[part 1 of 6: package /DBC_SysDesc_P_CANFD/Pkg_Cluster]
AUTOSAR XML (schema 4-2-2)
package /DBC_SysDesc_P_CANFD/Pkg_Cluster
  can cluster P_CANFD: baudrate=500000, protocol-name=CAN, can-fd-baudrate=2000000
    can physical channel P_CANFD_Channel: comm-connectors=Conn_P_CANFD_MVCU
      frame EMS_0xBE: id 0xBE, to MVCU, frame-length=32, can-addressing-mode=STANDARD, can-fd-frame-support=true, can-frame-rx-behavior=CAN-FD
        carries pdu EMS_0xBE: packing-byte-order=little-endian, start-position=0, update-indication-bit-position=-1
        pdu EMS_0xBE: length=32, transmission-mode-false-timing=cyclic-timing={time-offset=0.0, time-period=0.01}, transmission-mode-true-timing=cyclic-timing={time-offset=0.0, time-period=0.01}
          transmission-mode-conditions:
            {data-filter={data-filter-type=ALWAYS, max=255, min=0, offset=0}, i-signal-in-i-pdu=EMS_CRC_BE}
            {data-filter={data-filter-type=ALWAYS, max=15, min=0, offset=0}, i-signal-in-i-pdu=EMS_RollingCounter_BE}
            {data-filter={data-filter-type=ALWAYS, max=7, min=0, offset=0}, i-signal-in-i-pdu=EMS_EngineSts}
            {data-filter={data-filter-type=ALWAYS, max=3, min=0, offset=0}, i-signal-in-i-pdu=ECM_FaultLevel}
            {data-filter={data-filter-type=ALWAYS, max=1, min=0, offset=0}, i-signal-in-i-pdu=ECM_ActualEngineTorqueValid}
            {data-filter={data-filter-type=NEW-IS-WITHIN, max=1022, min=0}, i-signal-in-i-pdu=ECM_EngineTorqueLoss}
            {data-filter={data-filter-type=NEW-IS-WITHIN, max=4094, min=0}, i-signal-in-i-pdu=ECM_ActualEngineTorque}
            {data-filter={data-filter-type=NEW-IS-WITHIN, max=4094, min=0}, i-signal-in-i-pdu=ECM_EngineTorqueMax}
            {data-filter={data-filter-type=NEW-IS-WITHIN, max=4094, min=0}, i-signal-in-i-pdu=ECM_EngineTorqueMin}
            {data-filter={data-filter-type=NEW-IS-WITHIN, max=8191, min=0, offset=0}, i-signal-in-i-pdu=ECM_EngineSpeed}
            {data-filter={data-filter-type=ALWAYS, max=1, min=0, offset=0}, i-signal-in-i-pdu=ECM_EngineSpeedValid}
            {data-filter={data-filter-type=ALWAYS, max=1, min=0, offset=0}, i-signal-in-i-pdu=ECM_EngineStopAllow}
            {data-filter={data-filter-type=ALWAYS, max=1, min=0, offset=0}, i-signal-in-i-pdu=ECM_EngineOilPressureLow}
            {data-filter={data-filter-type=ALWAYS, max=1, min=0, offset=0}, i-signal-in-i-pdu=ECM_EngineFuleCutoffSts}
            {data-filter={data-filter-type=ALWAYS, max=1, min=0, offset=0}, i-signal-in-i-pdu=ECM_EngineStartedCompleted}
            {data-filter={data-filter-type=ALWAYS, max=1, min=0, offset=0}, i-signal-in-i-pdu=ECM_CatalystWarmUpSts}
            {data-filter={data-filter-type=ALWAYS, max=1, min=0, offset=0}, i-signal-in-i-pdu=ECM_CatalystWarmUpReq}
            {data-filter={data-filter-type=NEW-IS-WITHIN, max=4094, min=0, offset=0}, i-signal-in-i-pdu=ECM_IdleTargetSpeed}
            {data-filter={data-filter-type=ALWAYS, max=1, min=0, offset=0}, i-signal-in-i-pdu=ECM_IdleActive}
            {data-filter={data-filter-type=ALWAYS, max=7, min=0, offset=0}, i-signal-in-i-pdu=ECM_EngineStartReq}
            {data-filter={data-filter-type=NEW-IS-WITHIN, max=1023, min=0, offset=0}, i-signal-in-i-pdu=ECM_EngineStopInhibit}
            {data-filter={data-filter-type=ALWAYS, max=3, min=0, offset=0}, i-signal-in-i-pdu=ECM_GPFRegenlamp}
            {data-filter={data-filter-type=ALWAYS, max=255, min=0}, i-signal-in-i-pdu=ECM_EngineCoolantTemp}
            {data-filter={data-filter-type=ALWAYS, max=1, min=0, offset=0}, i-signal-in-i-pdu=ECM_EngineCoolantTempValid}
            {data-filter={data-filter-type=ALWAYS, max=3, min=0, offset=0}, i-signal-in-i-pdu=ECM_FVVSts}
            {data-filter={data-filter-type=ALWAYS, max=1, min=0, offset=0}, i-signal-in-i-pdu=ECM_learningReq}
            {data-filter={data-filter-type=ALWAYS, max=1, min=0, offset=0}, i-signal-in-i-pdu=ECM_EngineIdleStateRequest}
            {data-filter={data-filter-type=ALWAYS, max=1, min=0, offset=0}, i-signal-in-i-pdu=ECM_EngineDFCOConditionRequest}
            {data-filter={data-filter-type=ALWAYS, max=1, min=0, offset=0}, i-signal-in-i-pdu=ECM_GPFRegenReq}
            {data-filter={data-filter-type=ALWAYS, max=1, min=0, offset=0}, i-signal-in-i-pdu=ECM_SVSLampRequest}
            {data-filter={data-filter-type=NEW-IS-WITHIN, max=600, min=0}, i-signal-in-i-pdu=ECM_TankPressure}
            {data-filter={data-filter-type=ALWAYS, max=1, min=0, offset=0}, i-signal-in-i-pdu=ECM_TankPressureValid}
            {data-filter={data-filter-type=ALWAYS, max=3, min=0, offset=0}, i-signal-in-i-pdu=ECM_MilLampRequest}
            {data-filter={data-filter-type=ALWAYS, max=3, min=0, offset=0}, i-signal-in-i-pdu=ECM_ToothlearningSucValid}
            {data-filter={data-filter-type=ALWAYS, max=1, min=0, offset=0}, i-signal-in-i-pdu=ECM_FuelCloseLoopSts}
            {data-filter={data-filter-type=ALWAYS, max=100, min=0, offset=0}, i-signal-in-i-pdu=ECM_RestrictorOpenValue}
            {data-filter={data-filter-type=ALWAYS, max=1, min=0, offset=0}, i-signal-in-i-pdu=ECM_FuelLevelSensorValid}
            {data-filter={data-filter-type=NEW-IS-WITHIN, max=1000, min=0, offset=0}, i-signal-in-i-pdu=ECM_FuelLevel}
            {data-filter={data-filter-type=ALWAYS, max=1, min=0, offset=0}, i-signal-in-i-pdu=ECM_SelfCheckSt}
            {data-filter={data-filter-type=ALWAYS, max=1, min=0, offset=0}, i-signal-in-i-pdu=ECM_PCVPipeDiagReq}
            {data-filter={data-filter-type=NEW-IS-WITHIN, max=1000, min=0, offset=0}, i-signal-in-i-pdu=ECM_CalculatedLoad}
            {data-filter={data-filter-type=ALWAYS, max=254, min=0, offset=0}, i-signal-in-i-pdu=ECM_ClearingSparkcarbonedRequest}
            {data-filter={data-filter-type=ALWAYS, max=3, min=0, offset=0}, i-signal-in-i-pdu=ECM_AirPressure}
            {data-filter={data-filter-type=ALWAYS, max=100, min=0, offset=0}, i-signal-in-i-pdu=ECM_FanSts}
          signal EMS_CRC_BE: start 0, 8 bit, little-endian, init-value=0, base-type=uint8, implementation-data-type=DT_EMS_CRC_BE, update-indication-bit-position=-1, to MVCU
          signal EMS_RollingCounter_BE: start 8, 4 bit, little-endian, init-value=0, base-type=uint8, implementation-data-type=DT_EMS_RollingCounter_BE, update-indication-bit-position=-1, to MVCU
          signal EMS_EngineSts: start 16, 3 bit, little-endian, init-value=0, base-type=uint8, implementation-data-type=DT_EMS_EngineSts, update-indication-bit-position=-1, to MVCU
          signal ECM_FaultLevel: start 19, 2 bit, little-endian, init-value=0, base-type=uint8, implementation-data-type=DT_ECM_FaultLevel, update-indication-bit-position=-1, to MVCU
          signal ECM_ActualEngineTorqueValid: start 21, 1 bit, little-endian, init-value=0, base-type=uint8, implementation-data-type=DT_ECM_ActualEngineTorqueValid, update-indication-bit-position=-1, to MVCU
          signal ECM_EngineTorqueLoss: start 22, 10 bit, little-endian, init-value=0, base-type=uint16, implementation-data-type=DT_ECM_EngineTorqueLoss, update-indication-bit-position=-1, to MVCU
          signal ECM_ActualEngineTorque: start 32, 12 bit, little-endian, init-value=0, base-type=uint16, implementation-data-type=DT_ECM_ActualEngineTorque, update-indication-bit-position=-1, to MVCU
          signal ECM_EngineTorqueMax: start 44, 12 bit, little-endian, init-value=0, base-type=uint16, implementation-data-type=DT_ECM_EngineTorqueMax, update-indication-bit-position=-1, to MVCU
          signal ECM_EngineTorqueMin: start 56, 12 bit, little-endian, init-value=0, base-type=uint16, implementation-data-type=DT_ECM_EngineTorqueMin, update-indication-bit-position=-1, to MVCU
          signal ECM_EngineSpeed: start 68, 13 bit, little-endian, init-value=0, base-type=uint16, implementation-data-type=DT_ECM_EngineSpeed, update-indication-bit-position=-1, to MVCU
          signal ECM_EngineSpeedValid: start 81, 1 bit, little-endian, init-value=0, base-type=uint8, implementation-data-type=DT_ECM_EngineSpeedValid, update-indication-bit-position=-1, to MVCU
          signal ECM_EngineStopAllow: start 82, 1 bit, little-endian, init-value=0, base-type=uint8, implementation-data-type=DT_ECM_EngineStopAllow, update-indication-bit-position=-1, to MVCU
          signal ECM_EngineOilPressureLow: start 83, 1 bit, little-endian, init-value=0, base-type=uint8, implementation-data-type=DT_ECM_EngineOilPressureLow, update-indication-bit-position=-1, to MVCU
          signal ECM_EngineFuleCutoffSts: start 84, 1 bit, little-endian, init-value=0, base-type=uint8, implementation-data-type=DT_ECM_EngineFuleCutoffSts, update-indication-bit-position=-1, to MVCU
          signal ECM_EngineStartedCompleted: start 85, 1 bit, little-endian, init-value=0, base-type=uint8, implementation-data-type=DT_ECM_EngineStartedCompleted, update-indication-bit-position=-1, to MVCU
          signal ECM_CatalystWarmUpSts: start 86, 1 bit, little-endian, init-value=0, base-type=uint8, implementation-data-type=DT_ECM_CatalystWarmUpSts, update-indication-bit-position=-1, to MVCU
          signal ECM_CatalystWarmUpReq: start 87, 1 bit, little-endian, init-value=0, base-type=uint8, implementation-data-type=DT_ECM_CatalystWarmUpReq, update-indication-bit-position=-1, to MVCU
          signal ECM_IdleTargetSpeed: start 88, 12 bit, little-endian, init-value=0, base-type=uint16, implementation-data-type=DT_ECM_IdleTargetSpeed, update-indication-bit-position=-1, to MVCU
          signal ECM_IdleActive: start 100, 1 bit, little-endian, init-value=0, base-type=uint8, implementation-data-type=DT_ECM_IdleActive, update-indication-bit-position=-1, to MVCU
          signal ECM_EngineStartReq: start 101, 3 bit, little-endian, init-value=0, base-type=uint8, implementation-data-type=DT_ECM_EngineStartReq, update-indication-bit-position=-1, to MVCU
          signal ECM_EngineStopInhibit: start 104, 10 bit, little-endian, init-value=0, base-type=uint16, implementation-data-type=DT_ECM_EngineStopInhibit, update-indication-bit-position=-1, to MVCU
          signal ECM_GPFRegenlamp: start 114, 2 bit, little-endian, init-value=0, base-type=uint8, implementation-data-type=DT_ECM_GPFRegenlamp, update-indication-bit-position=-1, to MVCU
          signal ECM_EngineCoolantTemp: start 136, 8 bit, little-endian, init-value=0, base-type=uint8, implementation-data-type=DT_ECM_EngineCoolantTemp, update-indication-bit-position=-1, to MVCU
          signal ECM_EngineCoolantTempValid: start 144, 1 bit, little-endian, init-value=0, base-type=uint8, implementation-data-type=DT_ECM_EngineCoolantTempValid, update-indication-bit-position=-1, to MVCU
          signal ECM_FVVSts: start 145, 2 bit, little-endian, init-value=0, base-type=uint8, implementation-data-type=DT_ECM_FVVSts, update-indication-bit-position=-1, to MVCU
          signal ECM_learningReq: start 147, 1 bit, little-endian, init-value=0, base-type=uint8, implementation-data-type=DT_ECM_learningReq, update-indication-bit-position=-1, to MVCU
          signal ECM_EngineIdleStateRequest: start 148, 1 bit, little-endian, init-value=0, base-type=uint8, implementation-data-type=DT_ECM_EngineIdleStateRequest, update-indication-bit-position=-1, to MVCU
          signal ECM_EngineDFCOConditionRequest: start 149, 1 bit, little-endian, init-value=0, base-type=uint8, implementation-data-type=DT_ECM_EngineDFCOConditionRequest, update-indication-bit-position=-1, to MVCU
          signal ECM_GPFRegenReq: start 150, 1 bit, little-endian, init-value=0, base-type=uint8, implementation-data-type=DT_ECM_GPFRegenReq, update-indication-bit-position=-1, to MVCU
          signal ECM_SVSLampRequest: start 151, 1 bit, little-endian, init-value=0, base-type=uint8, implementation-data-type=DT_ECM_SVSLampRequest, update-indication-bit-position=-1, to MVCU
          signal ECM_TankPressure: start 152, 10 bit, little-endian, init-value=0, base-type=uint16, implementation-data-type=DT_ECM_TankPressure, update-indication-bit-position=-1, to MVCU
          signal ECM_TankPressureValid: start 162, 1 bit, little-endian, init-value=0, base-type=uint8, implementation-data-type=DT_ECM_TankPressureValid, update-indication-bit-position=-1, to MVCU
          signal ECM_MilLampRequest: start 163, 2 bit, little-endian, init-value=0, base-type=uint8, implementation-data-type=DT_ECM_MilLampRequest, update-indication-bit-position=-1, to MVCU
          signal ECM_ToothlearningSucValid: start 165, 2 bit, little-endian, init-value=0, base-type=uint8, implementation-data-type=DT_ECM_ToothlearningSucValid, update-indication-bit-position=-1, to MVCU
          signal ECM_FuelCloseLoopSts: start 167, 1 bit, little-endian, init-value=0, base-type=uint8, implementation-data-type=DT_ECM_FuelCloseLoopSts, update-indication-bit-position=-1, to MVCU
          signal ECM_RestrictorOpenValue: start 168, 7 bit, little-endian, init-value=0, base-type=uint8, implementation-data-type=DT_ECM_RestrictorOpenValue, update-indication-bit-position=-1, to MVCU
          signal ECM_FuelLevelSensorValid: start 175, 1 bit, little-endian, init-value=0, base-type=uint8, implementation-data-type=DT_ECM_FuelLevelSensorValid, update-indication-bit-position=-1, to MVCU
          signal ECM_FuelLevel: start 176, 10 bit, little-endian, init-value=0, base-type=uint16, implementation-data-type=DT_ECM_FuelLevel, update-indication-bit-position=-1, to MVCU
          signal ECM_SelfCheckSt: start 186, 1 bit, little-endian, init-value=0, base-type=uint8, implementation-data-type=DT_ECM_SelfCheckSt, update-indication-bit-position=-1, to MVCU
          signal ECM_PCVPipeDiagReq: start 187, 1 bit, little-endian, init-value=0, base-type=uint8, implementation-data-type=DT_ECM_PCVPipeDiagReq, update-indication-bit-position=-1, to MVCU
          signal ECM_CalculatedLoad: start 190, 10 bit, little-endian, init-value=0, base-type=uint16, implementation-data-type=DT_ECM_CalculatedLoad, update-indication-bit-position=-1, to MVCU
          signal ECM_ClearingSparkcarbonedRequest: start 203, 2 bit, little-endian, init-value=0, base-type=uint8, implementation-data-type=DT_ECM_ClearingSparkcarbonedRequest, update-indication-bit-position=-1, to MVCU
          signal ECM_AirPressure: start 208, 8 bit, little-endian, init-value=0, base-type=uint8, implementation-data-type=DT_ECM_AirPressure, update-indication-bit-position=-1, to MVCU
          signal ECM_FanSts: start 216, 8 bit, little-endian, init-value=0, base-type=uint8, implementation-data-type=DT_ECM_FanSts, update-indication-bit-position=-1, to MVCU
      frame BMS_0x5B5: id 0x5B5, to MVCU, frame-length=64, can-addressing-mode=STANDARD, can-fd-frame-support=true, can-frame-rx-behavior=CAN-FD
        carries pdu BMS_0x5B5: packing-byte-order=little-endian, start-position=0, update-indication-bit-position=-1
        pdu BMS_0x5B5: length=64, transmission-mode-false-timing=cyclic-timing={time-offset=0.0, time-period=0.2}, transmission-mode-true-timing=cyclic-timing={time-offset=0.0, time-period=0.2}
          transmission-mode-conditions:
            {data-filter={data-filter-type=ALWAYS, max=250, min=0, offset=0}, i-signal-in-i-pdu=BMS_WkupVolt_DC12V}
            {data-filter={data-filter-type=ALWAYS, max=250, min=0, offset=0}, i-signal-in-i-pdu=BMS_WkupVolt_AC12V}
            {data-filter={data-filter-type=NEW-IS-WITHIN, max=2000, min=0, offset=0}, i-signal-in-i-pdu=BMS_HVPackPosRelayExternalVolt}
            {data-filter={data-filter-type=NEW-IS-WITHIN, max=1000, min=0, offset=0}, i-signal-in-i-pdu=BMS_SOC_target}
            {data-filter={data-filter-type=NEW-IS-WITHIN, max=1000, min=0, offset=0}, i-signal-in-i-pdu=BMS_CorrectSOEPer}
            {data-filter={data-filter-type=ALWAYS, max=1, min=0, offset=0}, i-signal-in-i-pdu=BMS_SOCModifyFlag}
            {data-filter={data-filter-type=NEW-IS-WITHIN, max=16000000, min=0, offset=0}, i-signal-in-i-pdu=BMS_BMU_SoftwareVersion}
          signal BMS_WkupVolt_DC12V: start 64, 8 bit, little-endian, init-value=0, base-type=uint8, implementation-data-type=DT_BMS_WkupVolt_DC12V, update-indication-bit-position=-1, to MVCU
          signal BMS_WkupVolt_AC12V: start 72, 8 bit, little-endian, init-value=0, base-type=uint8, implementation-data-type=DT_BMS_WkupVolt_AC12V, update-indication-bit-position=-1, to MVCU
          signal BMS_HVPackPosRelayExternalVolt: start 152, 12 bit, little-endian, init-value=0, base-type=uint16, implementation-data-type=DT_BMS_HVPackPosRelayExternalVolt, update-indication-bit-position=-1, to MVCU
          signal BMS_SOC_target: start 192, 10 bit, little-endian, init-value=0, base-type=uint16, implementation-data-type=DT_BMS_SOC_target, update-indication-bit-position=-1, to MVCU
          signal BMS_CorrectSOEPer: start 202, 10 bit, little-endian, init-value=0, base-type=uint16, implementation-data-type=DT_BMS_CorrectSOEPer, update-indication-bit-position=-1, to MVCU
          signal BMS_SOCModifyFlag: start 212, 1 bit, little-endian, init-value=0, base-type=uint8, implementation-data-type=DT_BMS_SOCModifyFlag, update-indication-bit-position=-1, to MVCU
          signal BMS_BMU_SoftwareVersion: start 232, 24 bit, little-endian, init-value=0, base-type=uint32, implementation-data-type=DT_BMS_BMU_SoftwareVersion, update-indication-bit-position=-1, to MVCU
      frame OBC_0x316: id 0x316, to MVCU, frame-length=32, can-addressing-mode=STANDARD, can-fd-frame-support=true, can-frame-rx-behavior=CAN-FD
        carries pdu OBC_0x316: packing-byte-order=little-endian, start-position=0, update-indication-bit-position=-1
        pdu OBC_0x316: length=32, transmission-mode-false-timing=cyclic-timing={time-offset=0.0, time-period=0.2}, transmission-mode-true-timing=cyclic-timing={time-offset=0.0, time-period=0.2}
          transmission-mode-conditions:
            {data-filter={data-filter-type=ALWAYS, max=255, min=0, offset=0}, i-signal-in-i-pdu=OBC_CRC_316}
            {data-filter={data-filter-type=ALWAYS, max=15, min=0, offset=0}, i-signal-in-i-pdu=OBC_RollingCounter_316}
            {data-filter={data-filter-type=ALWAYS, max=7, min=0, offset=0}, i-signal-in-i-pdu=OBC_WorkSts}
            {data-filter={data-filter-type=ALWAYS, max=1, min=0, offset=0}, i-signal-in-i-pdu=OBC_StartSts}
            {data-filter={data-filter-type=ALWAYS, max=1, min=0, offset=0}, i-signal-in-i-pdu=OBC_DCSts}
            {data-filter={data-filter-type=ALWAYS, max=1, min=0, offset=0}, i-signal-in-i-pdu=OBC_ACChargeOutputSts}
            {data-filter={data-filter-type=NEW-IS-WITHIN, max=10000, min=0, offset=0}, i-signal-in-i-pdu=OBC_DCVolt}
            {data-filter={data-filter-type=ALWAYS, max=1, min=0, offset=0}, i-signal-in-i-pdu=OBC_HardwareSts}
            {data-filter={data-filter-type=NEW-IS-WITHIN, max=2000, min=0}, i-signal-in-i-pdu=OBC_DCCurr}
            {data-filter={data-filter-type=NEW-IS-WITHIN, max=8000, min=0, offset=0}, i-signal-in-i-pdu=OBC_ACVolt}
            {data-filter={data-filter-type=NEW-IS-WITHIN, max=2000, min=0}, i-signal-in-i-pdu=OBC_ACCurr}
            {data-filter={data-filter-type=ALWAYS, max=3, min=0, offset=0}, i-signal-in-i-pdu=OBC_CCConnectSts}
            {data-filter={data-filter-type=ALWAYS, max=1, min=0, offset=0}, i-signal-in-i-pdu=OBC_CPDutyCycleFault}
            {data-filter={data-filter-type=ALWAYS, max=100, min=0, offset=0}, i-signal-in-i-pdu=OBC_CPDutyCycleValue}
            {data-filter={data-filter-type=NEW-IS-WITHIN, max=1000, min=0}, i-signal-in-i-pdu=OBC_ACMaxPower}
            {data-filter={data-filter-type=ALWAYS, max=3, min=0, offset=0}, i-signal-in-i-pdu=OBC_ACPowerState}
          signal OBC_CRC_316: start 0, 8 bit, little-endian, init-value=0, base-type=uint8, implementation-data-type=DT_OBC_CRC_316, update-indication-bit-position=-1, to MVCU
          signal OBC_RollingCounter_316: start 8, 4 bit, little-endian, init-value=0, base-type=uint8, implementation-data-type=DT_OBC_RollingCounter_316, update-indication-bit-position=-1, to MVCU
          signal OBC_WorkSts: start 16, 3 bit, little-endian, init-value=0, base-type=uint8, implementation-data-type=DT_OBC_WorkSts, update-indication-bit-position=-1, to MVCU
          signal OBC_StartSts: start 19, 1 bit, little-endian, init-value=0, base-type=uint8, implementation-data-type=DT_OBC_StartSts, update-indication-bit-position=-1, to MVCU
          signal OBC_DCSts: start 20, 1 bit, little-endian, init-value=0, base-type=uint8, implementation-data-type=DT_OBC_DCSts, update-indication-bit-position=-1, to MVCU
          signal OBC_ACChargeOutputSts: start 23, 1 bit, little-endian, init-value=0, base-type=uint8, implementation-data-type=DT_OBC_ACChargeOutputSts, update-indication-bit-position=-1, to MVCU
          signal OBC_DCVolt: start 24, 14 bit, little-endian, init-value=0, base-type=uint16, implementation-data-type=DT_OBC_DCVolt, update-indication-bit-position=-1, to MVCU
          signal OBC_HardwareSts: start 39, 1 bit, little-endian, init-value=0, base-type=uint8, implementation-data-type=DT_OBC_HardwareSts, update-indication-bit-position=-1, to MVCU
          signal OBC_DCCurr: start 40, 11 bit, little-endian, init-value=0, base-type=uint16, implementation-data-type=DT_OBC_DCCurr, update-indication-bit-position=-1, to MVCU
          signal OBC_ACVolt: start 51, 13 bit, little-endian, init-value=0, base-type=uint16, implementation-data-type=DT_OBC_ACVolt, update-indication-bit-position=-1, to MVCU
          signal OBC_ACCurr: start 64, 11 bit, little-endian, init-value=0, base-type=uint16, implementation-data-type=DT_OBC_ACCurr, update-indication-bit-position=-1, to MVCU
          signal OBC_CCConnectSts: start 77, 2 bit, little-endian, init-value=0, base-type=uint8, implementation-data-type=DT_OBC_CCConnectSts, update-indication-bit-position=-1, to MVCU
          signal OBC_CPDutyCycleFault: start 79, 1 bit, little-endian, init-value=0, base-type=uint8, implementation-data-type=DT_OBC_CPDutyCycleFault, update-indication-bit-position=-1, to MVCU
          signal OBC_CPDutyCycleValue: start 80, 8 bit, little-endian, init-value=0, base-type=uint8, implementation-data-type=DT_OBC_CPDutyCycleValue, update-indication-bit-position=-1, to MVCU
          signal OBC_ACMaxPower: start 88, 10 bit, little-endian, init-value=0, base-type=uint16, implementation-data-type=DT_OBC_ACMaxPower, update-indication-bit-position=-1, to MVCU
          signal OBC_ACPowerState: start 158, 2 bit, little-endian, init-value=0, base-type=uint8, implementation-data-type=DT_OBC_ACPowerState, update-indication-bit-position=-1, to MVCU
      frame TMS_0x5FF: id 0x5FF, to MVCU, frame-length=16, can-addressing-mode=STANDARD, can-fd-frame-support=true, can-frame-rx-behavior=CAN-FD
        carries pdu TMS_0x5FF: packing-byte-order=little-endian, start-position=0, update-indication-bit-position=-1
        pdu TMS_0x5FF: length=16, transmission-mode-false-timing=cyclic-timing={time-offset=0.0, time-period=0.2}, transmission-mode-true-timing=cyclic-timing={time-offset=0.0, time-period=0.2}
          transmission-mode-conditions:
            {data-filter={data-filter-type=ALWAYS, max=128, min=0, offset=0}, i-signal-in-i-pdu=TMS_MCUMHeatPwrReq}
            {data-filter={data-filter-type=ALWAYS, max=1, min=0, offset=0}, i-signal-in-i-pdu=TMS_MCUMHeatModEnad}
            {data-filter={data-filter-type=ALWAYS, max=1, min=0, offset=0}, i-signal-in-i-pdu=TMS_VCU_MotSelfHeatEnReq}
            {data-filter={data-filter-type=ALWAYS, max=15, min=0, offset=0}, i-signal-in-i-pdu=TMS_VCU_MotSelfHeatLvlReq}
          signal TMS_MCUMHeatPwrReq: start 64, 8 bit, little-endian, init-value=0, base-type=uint8, implementation-data-type=DT_TMS_MCUMHeatPwrReq, update-indication-bit-position=-1, to MVCU
          signal TMS_MCUMHeatModEnad: start 72, 1 bit, little-endian, init-value=0, base-type=uint8, implementation-data-type=DT_TMS_MCUMHeatModEnad, update-indication-bit-position=-1, to MVCU
          signal TMS_VCU_MotSelfHeatEnReq: start 60, 1 bit, little-endian, init-value=0, base-type=uint8, implementation-data-type=DT_TMS_VCU_MotSelfHeatEnReq, update-indication-bit-position=-1, to MVCU
          signal TMS_VCU_MotSelfHeatLvlReq: start 73, 4 bit, little-endian, init-value=0, base-type=uint8, implementation-data-type=DT_TMS_VCU_MotSelfHeatLvlReq, update-indication-bit-position=-1, to MVCU
      frame TMS_0x5FE: id 0x5FE, to MVCU, frame-length=8, can-addressing-mode=STANDARD, can-fd-frame-support=true, can-frame-rx-behavior=CAN-FD
        carries pdu TMS_0x5FE: packing-byte-order=little-endian, start-position=0, update-indication-bit-position=-1
        pdu TMS_0x5FE: length=8, transmission-mode-condition{data-filter={data-filter-type=ALWAYS, max=3, min=0, offset=0}, i-signal-in-i-pdu=TMS_MilLampReq}, transmission-mode-false-timing=cyclic-timing={time-offset=0.0, time-period=0.2}, transmission-mode-true-timing=cyclic-timing={time-offset=0.0, time-period=0.2}
          signal TMS_MilLampReq: start 22, 2 bit, little-endian, init-value=0, base-type=uint8, implementation-data-type=DT_TMS_MilLampReq, update-indication-bit-position=-1, to MVCU
      frame BMS_0x5B1: id 0x5B1, to MVCU, frame-length=64, can-addressing-mode=STANDARD, can-fd-frame-support=true, can-frame-rx-behavior=CAN-FD
        carries pdu BMS_0x5B1: packing-byte-order=little-endian, start-position=0, update-indication-bit-position=-1
        pdu BMS_0x5B1: length=64, transmission-mode-false-timing=cyclic-timing={time-offset=0.0, time-period=1.0}, transmission-mode-true-timing=cyclic-timing={time-offset=0.0, time-period=1.0}
          transmission-mode-conditions:
            {data-filter={data-filter-type=NEW-IS-WITHIN, max=1000, min=0, offset=0}, i-signal-in-i-pdu=BMS_SOC_Real}
            {data-filter={data-filter-type=ALWAYS, max=15, min=0, offset=0}, i-signal-in-i-pdu=BMS_MODE_t}
            {data-filter={data-filter-type=ALWAYS, max=3, min=0, offset=0}, i-signal-in-i-pdu=BMS_VoltLoDeratLevel_NA}
            {data-filter={data-filter-type=ALWAYS, max=3, min=0, offset=0}, i-signal-in-i-pdu=BMS_VoltHiDeratLevel_NA}
          signal BMS_SOC_Real: start 320, 10 bit, little-endian, init-value=0, base-type=uint16, implementation-data-type=DT_BMS_SOC_Real, update-indication-bit-position=-1, to MVCU
          signal BMS_MODE_t: start 368, 4 bit, little-endian, init-value=0, base-type=uint8, implementation-data-type=DT_BMS_MODE_t, update-indication-bit-position=-1, to MVCU
          signal BMS_VoltLoDeratLevel_NA: start 466, 2 bit, little-endian, init-value=0, base-type=uint8, implementation-data-type=DT_BMS_VoltLoDeratLevel_NA, update-indication-bit-position=-1, to MVCU
          signal BMS_VoltHiDeratLevel_NA: start 468, 2 bit, little-endian, init-value=0, base-type=uint8, implementation-data-type=DT_BMS_VoltHiDeratLevel_NA, update-indication-bit-position=-1, to MVCU
      frame PTC_0x367: id 0x367, to MVCU, frame-length=16, can-addressing-mode=STANDARD, can-fd-frame-support=true, can-frame-rx-behavior=CAN-FD
        carries pdu PTC_0x367: packing-byte-order=little-endian, start-position=0, update-indication-bit-position=-1
        pdu PTC_0x367: length=16, transmission-mode-false-timing=cyclic-timing={time-offset=0.0, time-period=0.1}, transmission-mode-true-timing=cyclic-timing={time-offset=0.0, time-period=0.1}
          transmission-mode-conditions:
            {data-filter={data-filter-type=ALWAYS, max=1, min=0, offset=0}, i-signal-in-i-pdu=PTC_BscSts}
            {data-filter={data-filter-type=ALWAYS, max=15, min=0, offset=0}, i-signal-in-i-pdu=PTC_RollingCounter_367}
            {data-filter={data-filter-type=ALWAYS, max=1, min=0, offset=0}, i-signal-in-i-pdu=PTC_Fault}
            {data-filter={data-filter-type=ALWAYS, max=200, min=0, offset=0}, i-signal-in-i-pdu=PTC_Power}
            {data-filter={data-filter-type=ALWAYS, max=1, min=0, offset=0}, i-signal-in-i-pdu=PTC_HV_interlock_faultSt}
          signal PTC_BscSts: start 16, 1 bit, little-endian, init-value=0, base-type=uint8, implementation-data-type=DT_PTC_BscSts, update-indication-bit-position=-1, to MVCU
          signal PTC_RollingCounter_367: start 8, 4 bit, little-endian, init-value=0, base-type=uint8, implementation-data-type=DT_PTC_RollingCounter_367, update-indication-bit-position=-1, to MVCU
          signal PTC_Fault: start 17, 1 bit, little-endian, init-value=0, base-type=uint8, implementation-data-type=DT_PTC_Fault, update-indication-bit-position=-1, to MVCU
          signal PTC_Power: start 32, 8 bit, little-endian, init-value=0, base-type=uint8, implementation-data-type=DT_PTC_Power, update-indication-bit-position=-1, to MVCU
          signal PTC_HV_interlock_faultSt: start 75, 1 bit, little-endian, init-value=0, base-type=uint8, implementation-data-type=DT_PTC_HV_interlock_faultSt, update-indication-bit-position=-1, to MVCU
      frame MCU_0x5C7: id 0x5C7, to MVCU, frame-length=32, can-addressing-mode=STANDARD, can-fd-frame-support=true, can-frame-rx-behavior=CAN-FD
        carries pdu MCU_0x5C7: packing-byte-order=little-endian, start-position=0, update-indication-bit-position=-1
        pdu MCU_0x5C7: length=32, transmission-mode-false-timing=cyclic-timing={time-offset=0.0, time-period=0.01}, transmission-mode-true-timing=cyclic-timing={time-offset=0.0, time-period=0.01}
          transmission-mode-conditions:
            {data-filter={data-filter-type=NEW-IS-WITHIN, max=65535, min=0, offset=0}, i-signal-in-i-pdu=U16_CMD{1..4}}
            {data-filter={data-filter-type=NEW-IS-WITHIN, max=65535, min=0}, i-signal-in-i-pdu=S16_CMD{1..4}}
            {data-filter={data-filter-type=NEW-IS-WITHIN, max=65535, min=0}, i-signal-in-i-pdu=R16_CMD{1..4}}
            {data-filter={data-filter-type=ALWAYS, max=255, min=0, offset=0}, i-signal-in-i-pdu=U8_CMD{1..8}}
          signal U16_CMD1: start 0, 16 bit, little-endian, init-value=0, base-type=uint16, implementation-data-type=DT_U16_CMD1, update-indication-bit-position=-1, to MVCU
          signal U16_CMD2: start 16, 16 bit, little-endian, init-value=0, base-type=uint16, implementation-data-type=DT_U16_CMD2, update-indication-bit-position=-1, to MVCU
          signal U16_CMD3: start 32, 16 bit, little-endian, init-value=0, base-type=uint16, implementation-data-type=DT_U16_CMD3, update-indication-bit-position=-1, to MVCU
          signal U16_CMD4: start 48, 16 bit, little-endian, init-value=0, base-type=uint16, implementation-data-type=DT_U16_CMD4, update-indication-bit-position=-1, to MVCU
          signal S16_CMD1: start 64, 16 bit, little-endian, init-value=0, base-type=uint16, implementation-data-type=DT_S16_CMD1, update-indication-bit-position=-1, to MVCU
          signal S16_CMD2: start 80, 16 bit, little-endian, init-value=0, base-type=uint16, implementation-data-type=DT_S16_CMD2, update-indication-bit-position=-1, to MVCU
          signal S16_CMD3: start 96, 16 bit, little-endian, init-value=0, base-type=uint16, implementation-data-type=DT_S16_CMD3, update-indication-bit-position=-1, to MVCU
          signal S16_CMD4: start 112, 16 bit, little-endian, init-value=0, base-type=uint16, implementation-data-type=DT_S16_CMD4, update-indication-bit-position=-1, to MVCU
          signal R16_CMD1: start 128, 16 bit, little-endian, init-value=0, base-type=uint16, implementation-data-type=DT_R16_CMD1, update-indication-bit-position=-1, to MVCU
          signal R16_CMD2: start 144, 16 bit, little-endian, init-value=0, base-type=uint16, implementation-data-type=DT_R16_CMD2, update-indication-bit-position=-1, to MVCU
          signal R16_CMD3: start 160, 16 bit, little-endian, init-value=0, base-type=uint16, implementation-data-type=DT_R16_CMD3, update-indication-bit-position=-1, to MVCU
          signal R16_CMD4: start 176, 16 bit, little-endian, init-value=0, base-type=uint16, implementation-data-type=DT_R16_CMD4, update-indication-bit-position=-1, to MVCU
          signal U8_CMD1: start 192, 8 bit, little-endian, init-value=0, base-type=uint8, implementation-data-type=DT_U8_CMD1, update-indication-bit-position=-1, to MVCU
          signal U8_CMD2: start 200, 8 bit, little-endian, init-value=0, base-type=uint8, implementation-data-type=DT_U8_CMD2, update-indication-bit-position=-1, to MVCU
          signal U8_CMD3: start 208, 8 bit, little-endian, init-value=0, base-type=uint8, implementation-data-type=DT_U8_CMD3, update-indication-bit-position=-1, to MVCU
          signal U8_CMD4: start 216, 8 bit, little-endian, init-value=0, base-type=uint8, implementation-data-type=DT_U8_CMD4, update-indication-bit-position=-1, to MVCU
          signal U8_CMD5: start 224, 8 bit, little-endian, init-value=0, base-type=uint8, implementation-data-type=DT_U8_CMD5, update-indication-bit-position=-1, to MVCU
          signal U8_CMD6: start 232, 8 bit, little-endian, init-value=0, base-type=uint8, implementation-data-type=DT_U8_CMD6, update-indication-bit-position=-1, to MVCU
          signal U8_CMD7: start 240, 8 bit, little-endian, init-value=0, base-type=uint8, implementation-data-type=DT_U8_CMD7, update-indication-bit-position=-1, to MVCU
          signal U8_CMD8: start 248, 8 bit, little-endian, init-value=0, base-type=uint8, implementation-data-type=DT_U8_CMD8, update-indication-bit-position=-1, to MVCU
      frame MCU_0x5C5: id 0x5C5, to MVCU, frame-length=24, can-addressing-mode=STANDARD, can-fd-frame-support=true, can-frame-rx-behavior=CAN-FD
        carries pdu MCU_0x5C5: packing-byte-order=little-endian, start-position=0, update-indication-bit-position=-1
        pdu MCU_0x5C5: length=24, transmission-mode-false-timing=cyclic-timing={time-offset=0.0, time-period=0.01}, transmission-mode-true-timing=cyclic-timing={time-offset=0.0, time-period=0.01}
          transmission-mode-conditions:
            {data-filter={data-filter-type=ALWAYS, max=255, min=0, offset=0}, i-signal-in-i-pdu=EOL_ModeCMD_Data{0..5}}
            {data-filter={data-filter-type=ALWAYS, max=255, min=0, offset=0}, i-signal-in-i-pdu=EOL_ModeCMD_Enable}
            {data-filter={data-filter-type=ALWAYS, max=255, min=0, offset=0}, i-signal-in-i-pdu=EOL_ModeCMD_Check}
            {data-filter={data-filter-type=NEW-IS-WITHIN, max=400, min=0, offset=0}, i-signal-in-i-pdu=EOL_GainIden_UsApply}
            {data-filter={data-filter-type=ALWAYS, max=15, min=0, offset=0}, i-signal-in-i-pdu=EOL_MotClb_CtrlMode}
            {data-filter={data-filter-type=NEW-IS-WITHIN, max=36000, min=0, offset=0}, i-signal-in-i-pdu=MotClb_OfsSet}
            {data-filter={data-filter-type=NEW-IS-WITHIN, max=65535, min=0}, i-signal-in-i-pdu=EOL_MotClb_IsCMD}
            {data-filter={data-filter-type=NEW-IS-WITHIN, max=65535, min=0}, i-signal-in-i-pdu=EOL_MotClb_ThetaCMD}
            {data-filter={data-filter-type=NEW-IS-WITHIN, max=65535, min=0, offset=0}, i-signal-in-i-pdu=EOL_frqsync}
            {data-filter={data-filter-type=ALWAYS, max=3, min=0, offset=0}, i-signal-in-i-pdu=EOL_MotClb_Enable}
            {data-filter={data-filter-type=ALWAYS, max=1, min=0, offset=0}, i-signal-in-i-pdu=EOL_ActiveReleaseCmd}
            {data-filter={data-filter-type=ALWAYS, max=1, min=0, offset=0}, i-signal-in-i-pdu=MotClb_OfsAdjEn}
            {data-filter={data-filter-type=ALWAYS, max=3, min=0, offset=0}, i-signal-in-i-pdu=EOL_Asc_CMD}
            {data-filter={data-filter-type=ALWAYS, max=1, min=0, offset=0}, i-signal-in-i-pdu=EOL_PosDly_SnsrSupplier}
            {data-filter={data-filter-type=ALWAYS, max=1, min=0, offset=0}, i-signal-in-i-pdu=FstRcrd_Enable}
            {data-filter={data-filter-type=NEW-IS-WITHIN, max=8000, min=0, offset=0}, i-signal-in-i-pdu=GainIden_CurrRMS_Ref_U}
            {data-filter={data-filter-type=NEW-IS-WITHIN, max=8000, min=0, offset=0}, i-signal-in-i-pdu=GainIden_CurrRMS_Ref_V}
            {data-filter={data-filter-type=NEW-IS-WITHIN, max=8000, min=0, offset=0}, i-signal-in-i-pdu=GainIden_CurrRMS_Ref_W}
            {data-filter={data-filter-type=NEW-IS-WITHIN, max=400, min=0, offset=0}, i-signal-in-i-pdu=MCUMR_EOL_GainIden_UsApply}
            {data-filter={data-filter-type=ALWAYS, max=15, min=0, offset=0}, i-signal-in-i-pdu=MCUMR_EOL_MotClb_CtrlMode}
            {data-filter={data-filter-type=NEW-IS-WITHIN, max=36000, min=0, offset=0}, i-signal-in-i-pdu=MCUMR_MotClb_OfsSet}
            {data-filter={data-filter-type=NEW-IS-WITHIN, max=65535, min=0}, i-signal-in-i-pdu=MCUMR_EOL_MotClb_IsCMD}
            {data-filter={data-filter-type=NEW-IS-WITHIN, max=65535, min=0}, i-signal-in-i-pdu=MCUMR_EOL_MotClb_ThetaCMD}
            {data-filter={data-filter-type=NEW-IS-WITHIN, max=65535, min=0, offset=0}, i-signal-in-i-pdu=MCUMR_EOL_frqsync}
            {data-filter={data-filter-type=ALWAYS, max=3, min=0, offset=0}, i-signal-in-i-pdu=MCUMR_EOL_MotClb_Enable}
            {data-filter={data-filter-type=ALWAYS, max=1, min=0, offset=0}, i-signal-in-i-pdu=MCUMR_EOL_ActiveReleaseCmd}
            {data-filter={data-filter-type=ALWAYS, max=1, min=0, offset=0}, i-signal-in-i-pdu=MCUMR_MotClb_OfsAdjEn}
            {data-filter={data-filter-type=ALWAYS, max=3, min=0, offset=0}, i-signal-in-i-pdu=MCUMR_EOL_Asc_CMD}
            {data-filter={data-filter-type=ALWAYS, max=1, min=0, offset=0}, i-signal-in-i-pdu=MCUMR_EOL_PosDly_SnsrSupplier}
            {data-filter={data-filter-type=ALWAYS, max=1, min=0, offset=0}, i-signal-in-i-pdu=MCUMR_FstRcrd_Enable}
            {data-filter={data-filter-type=NEW-IS-WITHIN, max=8000, min=0, offset=0}, i-signal-in-i-pdu=MCUMR_GainIden_CurrRMS_Ref_U}
            {data-filter={data-filter-type=NEW-IS-WITHIN, max=8000, min=0, offset=0}, i-signal-in-i-pdu=MCUMR_GainIden_CurrRMS_Ref_V}
            {data-filter={data-filter-type=NEW-IS-WITHIN, max=8000, min=0, offset=0}, i-signal-in-i-pdu=MCUMR_GainIden_CurrRMS_Ref_W}
          signal EOL_ModeCMD_Data0: start 0, 8 bit, little-endian, init-value=0, base-type=uint8, implementation-data-type=DT_EOL_ModeCMD_Data0, update-indication-bit-position=-1, to MVCU
          signal EOL_ModeCMD_Data1: start 8, 8 bit, little-endian, init-value=0, base-type=uint8, implementation-data-type=DT_EOL_ModeCMD_Data1, update-indication-bit-position=-1, to MVCU
          signal EOL_ModeCMD_Data2: start 16, 8 bit, little-endian, init-value=0, base-type=uint8, implementation-data-type=DT_EOL_ModeCMD_Data2, update-indication-bit-position=-1, to MVCU
          signal EOL_ModeCMD_Data3: start 24, 8 bit, little-endian, init-value=0, base-type=uint8, implementation-data-type=DT_EOL_ModeCMD_Data3, update-indication-bit-position=-1, to MVCU
          signal EOL_ModeCMD_Data4: start 32, 8 bit, little-endian, init-value=0, base-type=uint8, implementation-data-type=DT_EOL_ModeCMD_Data4, update-indication-bit-position=-1, to MVCU
          signal EOL_ModeCMD_Data5: start 40, 8 bit, little-endian, init-value=0, base-type=uint8, implementation-data-type=DT_EOL_ModeCMD_Data5, update-indication-bit-position=-1, to MVCU
          signal EOL_ModeCMD_Enable: start 48, 8 bit, little-endian, init-value=0, base-type=uint8, implementation-data-type=DT_EOL_ModeCMD_Enable, update-indication-bit-position=-1, to MVCU
          signal EOL_ModeCMD_Check: start 56, 8 bit, little-endian, init-value=0, base-type=uint8, implementation-data-type=DT_EOL_ModeCMD_Check, update-indication-bit-position=-1, to MVCU
          signal EOL_GainIden_UsApply: start 64, 12 bit, little-endian, init-value=0, base-type=uint16, implementation-data-type=DT_EOL_GainIden_UsApply, update-indication-bit-position=-1, to MVCU
          signal EOL_MotClb_CtrlMode: start 76, 4 bit, little-endian, init-value=0, base-type=uint8, implementation-data-type=DT_EOL_MotClb_CtrlMode, update-indication-bit-position=-1, to MVCU
          signal MotClb_OfsSet: start 80, 16 bit, little-endian, init-value=0, base-type=uint16, implementation-data-type=DT_MotClb_OfsSet, update-indication-bit-position=-1, to MVCU
          signal EOL_MotClb_IsCMD: start 96, 16 bit, little-endian, init-value=0, base-type=uint16, implementation-data-type=DT_EOL_MotClb_IsCMD, update-indication-bit-position=-1, to MVCU
          signal EOL_MotClb_ThetaCMD: start 112, 16 bit, little-endian, init-value=0, base-type=uint16, implementation-data-type=DT_EOL_MotClb_ThetaCMD, update-indication-bit-position=-1, to MVCU
          signal EOL_frqsync: start 128, 16 bit, little-endian, init-value=0, base-type=uint16, implementation-data-type=DT_EOL_frqsync, update-indication-bit-position=-1, to MVCU
          signal EOL_MotClb_Enable: start 144, 2 bit, little-endian, init-value=0, base-type=uint8, implementation-data-type=DT_EOL_MotClb_Enable, update-indication-bit-position=-1, to MVCU
          signal EOL_ActiveReleaseCmd: start 146, 1 bit, little-endian, init-value=0, base-type=uint8, implementation-data-type=DT_EOL_ActiveReleaseCmd, update-indication-bit-position=-1, to MVCU
          signal MotClb_OfsAdjEn: start 147, 1 bit, little-endian, init-value=0, base-type=uint8, implementation-data-type=DT_MotClb_OfsAdjEn, update-indication-bit-position=-1, to MVCU
          signal EOL_Asc_CMD: start 148, 2 bit, little-endian, init-value=0, base-type=uint8, implementation-data-type=DT_EOL_Asc_CMD, update-indication-bit-position=-1, to MVCU
          signal EOL_PosDly_SnsrSupplier: start 150, 1 bit, little-endian, init-value=0, base-type=uint8, implementation-data-type=DT_EOL_PosDly_SnsrSupplier, update-indication-bit-position=-1, to MVCU
          signal FstRcrd_Enable: start 151, 1 bit, little-endian, init-value=0, base-type=uint8, implementation-data-type=DT_FstRcrd_Enable, update-indication-bit-position=-1, to MVCU
          signal GainIden_CurrRMS_Ref_U: start 152, 13 bit, little-endian, init-value=0, base-type=uint16, implementation-data-type=DT_GainIden_CurrRMS_Ref_U, update-indication-bit-position=-1, to MVCU
          signal GainIden_CurrRMS_Ref_V: start 165, 13 bit, little-endian, init-value=0, base-type=uint16, implementation-data-type=DT_GainIden_CurrRMS_Ref_V, update-indication-bit-position=-1, to MVCU
          signal GainIden_CurrRMS_Ref_W: start 178, 13 bit, little-endian, init-value=0, base-type=uint16, implementation-data-type=DT_GainIden_CurrRMS_Ref_W, update-indication-bit-position=-1, to MVCU
          signal MCUMR_EOL_GainIden_UsApply: start 192, 12 bit, little-endian, init-value=0, base-type=uint16, implementation-data-type=DT_MCUMR_EOL_GainIden_UsApply, update-indication-bit-position=-1, to MVCU
          signal MCUMR_EOL_MotClb_CtrlMode: start 204, 4 bit, little-endian, init-value=0, base-type=uint8, implementation-data-type=DT_MCUMR_EOL_MotClb_CtrlMode, update-indication-bit-position=-1, to MVCU
          signal MCUMR_MotClb_OfsSet: start 208, 16 bit, little-endian, init-value=0, base-type=uint16, implementation-data-type=DT_MCUMR_MotClb_OfsSet, update-indication-bit-position=-1, to MVCU
          signal MCUMR_EOL_MotClb_IsCMD: start 224, 16 bit, little-endian, init-value=0, base-type=uint16, implementation-data-type=DT_MCUMR_EOL_MotClb_IsCMD, update-indication-bit-position=-1, to MVCU
          signal MCUMR_EOL_MotClb_ThetaCMD: start 240, 16 bit, little-endian, init-value=0, base-type=uint16, implementation-data-type=DT_MCUMR_EOL_MotClb_ThetaCMD, update-indication-bit-position=-1, to MVCU
          signal MCUMR_EOL_frqsync: start 256, 16 bit, little-endian, init-value=0, base-type=uint16, implementation-data-type=DT_MCUMR_EOL_frqsync, update-indication-bit-position=-1, to MVCU
          signal MCUMR_EOL_MotClb_Enable: start 272, 2 bit, little-endian, init-value=0, base-type=uint8, implementation-data-type=DT_MCUMR_EOL_MotClb_Enable, update-indication-bit-position=-1, to MVCU
          signal MCUMR_EOL_ActiveReleaseCmd: start 274, 1 bit, little-endian, init-value=0, base-type=uint8, implementation-data-type=DT_MCUMR_EOL_ActiveReleaseCmd, update-indication-bit-position=-1, to MVCU
          signal MCUMR_MotClb_OfsAdjEn: start 275, 1 bit, little-endian, init-value=0, base-type=uint8, implementation-data-type=DT_MCUMR_MotClb_OfsAdjEn, update-indication-bit-position=-1, to MVCU
          signal MCUMR_EOL_Asc_CMD: start 276, 2 bit, little-endian, init-value=0, base-type=uint8, implementation-data-type=DT_MCUMR_EOL_Asc_CMD, update-indication-bit-position=-1, to MVCU
          signal MCUMR_EOL_PosDly_SnsrSupplier: start 278, 1 bit, little-endian, init-value=0, base-type=uint8, implementation-data-type=DT_MCUMR_EOL_PosDly_SnsrSupplier, update-indication-bit-position=-1, to MVCU
          signal MCUMR_FstRcrd_Enable: start 279, 1 bit, little-endian, init-value=0, base-type=uint8, implementation-data-type=DT_MCUMR_FstRcrd_Enable, update-indication-bit-position=-1, to MVCU
          signal MCUMR_GainIden_CurrRMS_Ref_U: start 280, 13 bit, little-endian, init-value=0, base-type=uint16, implementation-data-type=DT_MCUMR_GainIden_CurrRMS_Ref_U, update-indication-bit-position=-1, to MVCU
          signal MCUMR_GainIden_CurrRMS_Ref_V: start 293, 13 bit, little-endian, init-value=0, base-type=uint16, implementation-data-type=DT_MCUMR_GainIden_CurrRMS_Ref_V, update-indication-bit-position=-1, to MVCU
          signal MCUMR_GainIden_CurrRMS_Ref_W: start 306, 13 bit, little-endian, init-value=0, base-type=uint16, implementation-data-type=DT_MCUMR_GainIden_CurrRMS_Ref_W, update-indication-bit-position=-1, to MVCU
      frame CCM_0x36A: id 0x36A, to MVCU, frame-length=16, can-addressing-mode=STANDARD, can-fd-frame-support=true, can-frame-rx-behavior=CAN-FD
        carries pdu CCM_0x36A: packing-byte-order=little-endian, start-position=0, update-indication-bit-position=-1
        pdu CCM_0x36A: length=16, transmission-mode-false-timing=cyclic-timing={time-offset=0.0, time-period=0.1}, transmission-mode-true-timing=cyclic-timing={time-offset=0.0, time-period=0.1}
          transmission-mode-conditions:
            {data-filter={data-filter-type=NEW-IS-WITHIN, max=1000, min=0, offset=0}, i-signal-in-i-pdu=CCM_Volt}
            {data-filter={data-filter-type=ALWAYS, max=15, min=0, offset=0}, i-signal-in-i-pdu=CCM_RollingCounter_36A}
            {data-filter={data-filter-type=ALWAYS, max=7, min=0, offset=0}, i-signal-in-i-pdu=CCM_BaseState}
            {data-filter={data-filter-type=ALWAYS, max=240, min=0, offset=0}, i-signal-in-i-pdu=CCM_Power}
            {data-filter={data-filter-type=ALWAYS, max=240, min=0, offset=0}, i-signal-in-i-pdu=CCM_APTC_BscSts}
            {data-filter={data-filter-type=ALWAYS, max=1, min=0, offset=0}, i-signal-in-i-pdu=CCM_APTC_Power}
          signal CCM_Volt: start 24, 10 bit, little-endian, init-value=0, base-type=uint16, implementation-data-type=DT_CCM_Volt, update-indication-bit-position=-1, to MVCU
          signal CCM_RollingCounter_36A: start 8, 4 bit, little-endian, init-value=0, base-type=uint8, implementation-data-type=DT_CCM_RollingCounter_36A, update-indication-bit-position=-1, to MVCU
          signal CCM_BaseState: start 34, 3 bit, little-endian, init-value=0, base-type=uint8, implementation-data-type=DT_CCM_BaseState, update-indication-bit-position=-1, to MVCU
          signal CCM_Power: start 56, 8 bit, little-endian, init-value=0, base-type=uint8, implementation-data-type=DT_CCM_Power, update-indication-bit-position=-1, to MVCU
          signal CCM_APTC_BscSts: start 102, 1 bit, little-endian, init-value=0, base-type=uint8, implementation-data-type=DT_CCM_APTC_BscSts, update-indication-bit-position=-1, to MVCU
          signal CCM_APTC_Power: start 112, 8 bit, little-endian, init-value=0, base-type=uint8, implementation-data-type=DT_CCM_APTC_Power, update-indication-bit-position=-1, to MVCU
      frame TMS_0x561: id 0x561, to MVCU, frame-length=32, can-addressing-mode=STANDARD, can-fd-frame-support=true, can-frame-rx-behavior=CAN-FD
        carries pdu TMS_0x561: packing-byte-order=little-endian, start-position=0, update-indication-bit-position=-1
        pdu TMS_0x561: length=32, transmission-mode-false-timing=cyclic-timing={time-offset=0.0, time-period=0.5}, transmission-mode-true-timing=cyclic-timing={time-offset=0.0, time-period=0.5}
          transmission-mode-conditions:
            {data-filter={data-filter-type=ALWAYS, max=250, min=0}, i-signal-in-i-pdu=TMS_MCUOutTemp}
            {data-filter={data-filter-type=ALWAYS, max=250, min=0}, i-signal-in-i-pdu=TMS_MCUMIntelTemp}
            {data-filter={data-filter-type=ALWAYS, max=250, min=0}, i-signal-in-i-pdu=TMS_MCUSIntelTemp}
          signal TMS_MCUOutTemp: start 16, 8 bit, little-endian, init-value=0, base-type=uint8, implementation-data-type=DT_TMS_MCUOutTemp, update-indication-bit-position=-1, to MVCU
          signal TMS_MCUMIntelTemp: start 48, 8 bit, little-endian, init-value=0, base-type=uint8, implementation-data-type=DT_TMS_MCUMIntelTemp, update-indication-bit-position=-1, to MVCU
          signal TMS_MCUSIntelTemp: start 56, 8 bit, little-endian, init-value=0, base-type=uint8, implementation-data-type=DT_TMS_MCUSIntelTemp, update-indication-bit-position=-1, to MVCU
      frame HPCGW_0x13A: id 0x13A, to MVCU, frame-length=16, can-addressing-mode=STANDARD, can-fd-frame-support=true, can-frame-rx-behavior=CAN-FD
        carries pdu HPCGW_0x13A: packing-byte-order=little-endian, start-position=0, update-indication-bit-position=-1
        pdu HPCGW_0x13A: length=16, transmission-mode-false-timing=cyclic-timing={time-offset=0.0, time-period=0.02}, transmission-mode-true-timing=cyclic-timing={time-offset=0.0, time-period=0.02}
          transmission-mode-conditions:
            {data-filter={data-filter-type=ALWAYS, max=255, min=0, offset=0}, i-signal-in-i-pdu=GW_CRC_13A}
            {data-filter={data-filter-type=ALWAYS, max=15, min=0, offset=0}, i-signal-in-i-pdu=GW_RollingCounter_13A}
            {data-filter={data-filter-type=NEW-IS-WITHIN, max=45000, min=0, offset=0}, i-signal-in-i-pdu=GW_IBC_VehicleSpeed}
            {data-filter={data-filter-type=ALWAYS, max=1, min=0, offset=0}, i-signal-in-i-pdu=GW_IBC_VehicleSpeedVD}
            {data-filter={data-filter-type=ALWAYS, max=3, min=0, offset=0}, i-signal-in-i-pdu=GW_IBC_AVHStatus}
            {data-filter={data-filter-type=ALWAYS, max=1, min=0, offset=0}, i-signal-in-i-pdu=GW_IBC_RAB_Avatiable}
            {data-filter={data-filter-type=ALWAYS, max=1, min=0, offset=0}, i-signal-in-i-pdu=GW_IBC_RAB_Active}
            {data-filter={data-filter-type=NEW-IS-WITHIN, max=45000, min=0, offset=0}, i-signal-in-i-pdu=GW_IBC_FLWheelSpeedKPH}
            {data-filter={data-filter-type=NEW-IS-WITHIN, max=45000, min=0, offset=0}, i-signal-in-i-pdu=GW_IBC_FRWheelSpeedKPH}
            {data-filter={data-filter-type=NEW-IS-WITHIN, max=45000, min=0, offset=0}, i-signal-in-i-pdu=GW_IBC_RLWheelSpeedKPH}
            {data-filter={data-filter-type=NEW-IS-WITHIN, max=45000, min=0, offset=0}, i-signal-in-i-pdu=GW_IBC_RRWheelSpeedKPH}
            {data-filter={data-filter-type=ALWAYS, max=3, min=0, offset=0}, i-signal-in-i-pdu=GW_IBC_FLWheelDirection}
            {data-filter={data-filter-type=ALWAYS, max=3, min=0, offset=0}, i-signal-in-i-pdu=GW_IBC_FRWheelDirection}
            {data-filter={data-filter-type=ALWAYS, max=3, min=0, offset=0}, i-signal-in-i-pdu=GW_IBC_RLWheelDirection}
            {data-filter={data-filter-type=ALWAYS, max=3, min=0, offset=0}, i-signal-in-i-pdu=GW_IBC_RRWheelDirection}
            {data-filter={data-filter-type=ALWAYS, max=1, min=0, offset=0}, i-signal-in-i-pdu=GW_IBC_FLWheelSpeedVD}
            {data-filter={data-filter-type=ALWAYS, max=1, min=0, offset=0}, i-signal-in-i-pdu=GW_IBC_FRWheelSpeedVD}
            {data-filter={data-filter-type=ALWAYS, max=1, min=0, offset=0}, i-signal-in-i-pdu=GW_IBC_RLWheelSpeedVD}
            {data-filter={data-filter-type=ALWAYS, max=1, min=0, offset=0}, i-signal-in-i-pdu=GW_IBC_RRWheelSpeedVD}
            {data-filter={data-filter-type=ALWAYS, max=1, min=0, offset=0}, i-signal-in-i-pdu=GW_IBC_PlungerPressure_Q}
            {data-filter={data-filter-type=NEW-IS-WITHIN, max=2046, min=0, offset=0}, i-signal-in-i-pdu=GW_IBC_PlungerPressure}
          signal GW_CRC_13A: start 0, 8 bit, little-endian, init-value=0, base-type=uint8, implementation-data-type=DT_GW_CRC_13A, update-indication-bit-position=-1, to MVCU
          signal GW_RollingCounter_13A: start 8, 4 bit, little-endian, init-value=0, base-type=uint8, implementation-data-type=DT_GW_RollingCounter_13A, update-indication-bit-position=-1, to MVCU
          signal GW_IBC_VehicleSpeed: start 16, 16 bit, little-endian, init-value=0, base-type=uint16, implementation-data-type=DT_GW_IBC_VehicleSpeed, update-indication-bit-position=-1, to MVCU
          signal GW_IBC_VehicleSpeedVD: start 32, 1 bit, little-endian, init-value=0, base-type=uint8, implementation-data-type=DT_GW_IBC_VehicleSpeedVD, update-indication-bit-position=-1, to MVCU
          signal GW_IBC_AVHStatus: start 33, 2 bit, little-endian, init-value=0, base-type=uint8, implementation-data-type=DT_GW_IBC_AVHStatus, update-indication-bit-position=-1, to MVCU
          signal GW_IBC_RAB_Avatiable: start 35, 1 bit, little-endian, init-value=0, base-type=uint8, implementation-data-type=DT_GW_IBC_RAB_Avatiable, update-indication-bit-position=-1, to MVCU
          signal GW_IBC_RAB_Active: start 36, 1 bit, little-endian, init-value=0, base-type=uint8, implementation-data-type=DT_GW_IBC_RAB_Active, update-indication-bit-position=-1, to MVCU
          signal GW_IBC_FLWheelSpeedKPH: start 40, 16 bit, little-endian, init-value=0, base-type=uint16, implementation-data-type=DT_GW_IBC_FLWheelSpeedKPH, update-indication-bit-position=-1, to MVCU
          signal GW_IBC_FRWheelSpeedKPH: start 56, 16 bit, little-endian, init-value=0, base-type=uint16, implementation-data-type=DT_GW_IBC_FRWheelSpeedKPH, update-indication-bit-position=-1, to MVCU
          signal GW_IBC_RLWheelSpeedKPH: start 72, 16 bit, little-endian, init-value=0, base-type=uint16, implementation-data-type=DT_GW_IBC_RLWheelSpeedKPH, update-indication-bit-position=-1, to MVCU
          signal GW_IBC_RRWheelSpeedKPH: start 88, 16 bit, little-endian, init-value=0, base-type=uint16, implementation-data-type=DT_GW_IBC_RRWheelSpeedKPH, update-indication-bit-position=-1, to MVCU
          signal GW_IBC_FLWheelDirection: start 104, 2 bit, little-endian, init-value=0, base-type=uint8, implementation-data-type=DT_GW_IBC_FLWheelDirection, update-indication-bit-position=-1, to MVCU
          signal GW_IBC_FRWheelDirection: start 106, 2 bit, little-endian, init-value=0, base-type=uint8, implementation-data-type=DT_GW_IBC_FRWheelDirection, update-indication-bit-position=-1, to MVCU
          signal GW_IBC_RLWheelDirection: start 108, 2 bit, little-endian, init-value=0, base-type=uint8, implementation-data-type=DT_GW_IBC_RLWheelDirection, update-indication-bit-position=-1, to MVCU
          signal GW_IBC_RRWheelDirection: start 110, 2 bit, little-endian, init-value=0, base-type=uint8, implementation-data-type=DT_GW_IBC_RRWheelDirection, update-indication-bit-position=-1, to MVCU
          signal GW_IBC_FLWheelSpeedVD: start 112, 1 bit, little-endian, init-value=0, base-type=uint8, implementation-data-type=DT_GW_IBC_FLWheelSpeedVD, update-indication-bit-position=-1, to MVCU
          signal GW_IBC_FRWheelSpeedVD: start 113, 1 bit, little-endian, init-value=0, base-type=uint8, implementation-data-type=DT_GW_IBC_FRWheelSpeedVD, update-indication-bit-position=-1, to MVCU
          signal GW_IBC_RLWheelSpeedVD: start 114, 1 bit, little-endian, init-value=0, base-type=uint8, implementation-data-type=DT_GW_IBC_RLWheelSpeedVD, update-indication-bit-position=-1, to MVCU
          signal GW_IBC_RRWheelSpeedVD: start 115, 1 bit, little-endian, init-value=0, base-type=uint8, implementation-data-type=DT_GW_IBC_RRWheelSpeedVD, update-indication-bit-position=-1, to MVCU
          signal GW_IBC_PlungerPressure_Q: start 116, 1 bit, little-endian, init-value=0, base-type=uint8, implementation-data-type=DT_GW_IBC_PlungerPressure_Q, update-indication-bit-position=-1, to MVCU
          signal GW_IBC_PlungerPressure: start 117, 11 bit, little-endian, init-value=0, base-type=uint16, implementation-data-type=DT_GW_IBC_PlungerPressure, update-indication-bit-position=-1, to MVCU
      frame HPCBCM_0x291: id 0x291, to MVCU, frame-length=16, can-addressing-mode=STANDARD, can-fd-frame-support=true, can-frame-rx-behavior=CAN-FD
        carries pdu HPCBCM_0x291: packing-byte-order=little-endian, start-position=0, update-indication-bit-position=-1
        pdu HPCBCM_0x291: length=16, transmission-mode-false-timing=cyclic-timing={time-offset=0.0, time-period=0.02}, transmission-mode-true-timing=cyclic-timing={time-offset=0.0, time-period=0.02}
          transmission-mode-conditions:
            {data-filter={data-filter-type=ALWAYS, max=255, min=0, offset=0}, i-signal-in-i-pdu=BCM_CRC_291}
            {data-filter={data-filter-type=ALWAYS, max=1, min=0, offset=0}, i-signal-in-i-pdu=BCM_ShutdownMode}
            {data-filter={data-filter-type=ALWAYS, max=1, min=0, offset=0}, i-signal-in-i-pdu=BCM_NM_PNC_ON_1ADr_Sts}
            {data-filter={data-filter-type=ALWAYS, max=15, min=0, offset=0}, i-signal-in-i-pdu=BCM_RollingCounter_291}
            {data-filter={data-filter-type=ALWAYS, max=1, min=0, offset=0}, i-signal-in-i-pdu=BCM_KeyPosition_ON2A}
            {data-filter={data-filter-type=ALWAYS, max=1, min=0, offset=0}, i-signal-in-i-pdu=BCM_CcmHvilSts_ID291}
            {data-filter={data-filter-type=ALWAYS, max=1, min=0, offset=0}, i-signal-in-i-pdu=BCM_DriverDoorSts}
            {data-filter={data-filter-type=ALWAYS, max=1, min=0, offset=0}, i-signal-in-i-pdu=BCM_FLDoorSts}
            {data-filter={data-filter-type=ALWAYS, max=1, min=0, offset=0}, i-signal-in-i-pdu=BCM_FRDoorSts}
            {data-filter={data-filter-type=ALWAYS, max=1, min=0, offset=0}, i-signal-in-i-pdu=BCM_RLDoorSts}
            {data-filter={data-filter-type=ALWAYS, max=1, min=0, offset=0}, i-signal-in-i-pdu=BCM_RRDoorSts}
            {data-filter={data-filter-type=ALWAYS, max=1, min=0, offset=0}, i-signal-in-i-pdu=BCM_BackDoorSts}
            {data-filter={data-filter-type=ALWAYS, max=1, min=0, offset=0}, i-signal-in-i-pdu=BCM_ON2BRelaySts}
            {data-filter={data-filter-type=ALWAYS, max=1, min=0, offset=0}, i-signal-in-i-pdu=BCM_ON2CRelaySts}
            {data-filter={data-filter-type=ALWAYS, max=1, min=0, offset=0}, i-signal-in-i-pdu=BCM_ON2InitiativeSts}
            {data-filter={data-filter-type=ALWAYS, max=1, min=0, offset=0}, i-signal-in-i-pdu=BCM_VehicleRepairMode}
            {data-filter={data-filter-type=ALWAYS, max=3, min=0, offset=0}, i-signal-in-i-pdu=BCM_VehlockCtrl}
            {data-filter={data-filter-type=ALWAYS, max=1, min=0, offset=0}, i-signal-in-i-pdu=BCM_VehLockSts}
            {data-filter={data-filter-type=ALWAYS, max=3, min=0, offset=0}, i-signal-in-i-pdu=BCM_FuelTankLockReq}
            {data-filter={data-filter-type=ALWAYS, max=3, min=0, offset=0}, i-signal-in-i-pdu=BCM_ACChgLockCtrl}
            {data-filter={data-filter-type=ALWAYS, max=3, min=0, offset=0}, i-signal-in-i-pdu=BCM_ChargeLockCtrl}
            {data-filter={data-filter-type=ALWAYS, max=1, min=0, offset=0}, i-signal-in-i-pdu=BCM_DCChrgPwr_Sts_ID291}
            {data-filter={data-filter-type=ALWAYS, max=1, min=0, offset=0}, i-signal-in-i-pdu=BCM_ACChrgPwr_Sts_ID291}
            {data-filter={data-filter-type=ALWAYS, max=255, min=0, offset=0}, i-signal-in-i-pdu=BCM_DCChrgPwr_Volt_ID291}
            {data-filter={data-filter-type=ALWAYS, max=255, min=0, offset=0}, i-signal-in-i-pdu=BCM_ACChrgPwr_Volt_ID291}
            {data-filter={data-filter-type=ALWAYS, max=1, min=0, offset=0}, i-signal-in-i-pdu=BCM_KeyPosition_ON2B}
            {data-filter={data-filter-type=ALWAYS, max=1, min=0, offset=0}, i-signal-in-i-pdu=BCM_NM_PNC_ON_3Ch_Sts}
            {data-filter={data-filter-type=ALWAYS, max=3, min=0, offset=0}, i-signal-in-i-pdu=BCM_HighVoltageReq}
          signal BCM_CRC_291: start 0, 8 bit, little-endian, init-value=0, base-type=uint8, implementation-data-type=DT_BCM_CRC_291, update-indication-bit-position=-1, to MVCU
          signal BCM_ShutdownMode: start 15, 1 bit, little-endian, init-value=0, base-type=uint8, implementation-data-type=DT_BCM_ShutdownMode, update-indication-bit-position=-1, to MVCU
          signal BCM_NM_PNC_ON_1ADr_Sts: start 67, 1 bit, little-endian, init-value=0, base-type=uint8, implementation-data-type=DT_BCM_NM_PNC_ON_1ADr_Sts, update-indication-bit-position=-1, to MVCU
          signal BCM_RollingCounter_291: start 8, 4 bit, little-endian, init-value=0, base-type=uint8, implementation-data-type=DT_BCM_RollingCounter_291, update-indication-bit-position=-1, to MVCU
          signal BCM_KeyPosition_ON2A: start 18, 1 bit, little-endian, init-value=0, base-type=uint8, implementation-data-type=DT_BCM_KeyPosition_ON2A, update-indication-bit-position=-1, to MVCU
          signal BCM_CcmHvilSts_ID291: start 22, 1 bit, little-endian, init-value=0, base-type=uint8, implementation-data-type=DT_BCM_CcmHvilSts_ID291, update-indication-bit-position=-1, to MVCU
          signal BCM_DriverDoorSts: start 23, 1 bit, little-endian, init-value=0, base-type=uint8, implementation-data-type=DT_BCM_DriverDoorSts, update-indication-bit-position=-1, to MVCU
          signal BCM_FLDoorSts: start 24, 1 bit, little-endian, init-value=0, base-type=uint8, implementation-data-type=DT_BCM_FLDoorSts, update-indication-bit-position=-1, to MVCU
          signal BCM_FRDoorSts: start 25, 1 bit, little-endian, init-value=0, base-type=uint8, implementation-data-type=DT_BCM_FRDoorSts, update-indication-bit-position=-1, to MVCU
          signal BCM_RLDoorSts: start 26, 1 bit, little-endian, init-value=0, base-type=uint8, implementation-data-type=DT_BCM_RLDoorSts, update-indication-bit-position=-1, to MVCU
          signal BCM_RRDoorSts: start 27, 1 bit, little-endian, init-value=0, base-type=uint8, implementation-data-type=DT_BCM_RRDoorSts, update-indication-bit-position=-1, to MVCU
          signal BCM_BackDoorSts: start 28, 1 bit, little-endian, init-value=0, base-type=uint8, implementation-data-type=DT_BCM_BackDoorSts, update-indication-bit-position=-1, to MVCU
          signal BCM_ON2BRelaySts: start 30, 1 bit, little-endian, init-value=0, base-type=uint8, implementation-data-type=DT_BCM_ON2BRelaySts, update-indication-bit-position=-1, to MVCU
          signal BCM_ON2CRelaySts: start 31, 1 bit, little-endian, init-value=0, base-type=uint8, implementation-data-type=DT_BCM_ON2CRelaySts, update-indication-bit-position=-1, to MVCU
          signal BCM_ON2InitiativeSts: start 35, 1 bit, little-endian, init-value=0, base-type=uint8, implementation-data-type=DT_BCM_ON2InitiativeSts, update-indication-bit-position=-1, to MVCU
          signal BCM_VehicleRepairMode: start 36, 1 bit, little-endian, init-value=0, base-type=uint8, implementation-data-type=DT_BCM_VehicleRepairMode, update-indication-bit-position=-1, to MVCU
          signal BCM_VehlockCtrl: start 37, 2 bit, little-endian, init-value=0, base-type=uint8, implementation-data-type=DT_BCM_VehlockCtrl, update-indication-bit-position=-1, to MVCU
          signal BCM_VehLockSts: start 39, 1 bit, little-endian, init-value=0, base-type=uint8, implementation-data-type=DT_BCM_VehLockSts, update-indication-bit-position=-1, to MVCU
          signal BCM_FuelTankLockReq: start 40, 2 bit, little-endian, init-value=0, base-type=uint8, implementation-data-type=DT_BCM_FuelTankLockReq, update-indication-bit-position=-1, to MVCU
          signal BCM_ACChgLockCtrl: start 42, 2 bit, little-endian, init-value=0, base-type=uint8, implementation-data-type=DT_BCM_ACChgLockCtrl, update-indication-bit-position=-1, to MVCU
          signal BCM_ChargeLockCtrl: start 44, 2 bit, little-endian, init-value=0, base-type=uint8, implementation-data-type=DT_BCM_ChargeLockCtrl, update-indication-bit-position=-1, to MVCU
          signal BCM_DCChrgPwr_Sts_ID291: start 46, 1 bit, little-endian, init-value=0, base-type=uint8, implementation-data-type=DT_BCM_DCChrgPwr_Sts_ID291, update-indication-bit-position=-1, to MVCU
          signal BCM_ACChrgPwr_Sts_ID291: start 47, 1 bit, little-endian, init-value=0, base-type=uint8, implementation-data-type=DT_BCM_ACChrgPwr_Sts_ID291, update-indication-bit-position=-1, to MVCU
          signal BCM_DCChrgPwr_Volt_ID291: start 48, 8 bit, little-endian, init-value=0, base-type=uint8, implementation-data-type=DT_BCM_DCChrgPwr_Volt_ID291, update-indication-bit-position=-1, to MVCU
          signal BCM_ACChrgPwr_Volt_ID291: start 56, 8 bit, little-endian, init-value=0, base-type=uint8, implementation-data-type=DT_BCM_ACChrgPwr_Volt_ID291, update-indication-bit-position=-1, to MVCU
          signal BCM_KeyPosition_ON2B: start 64, 1 bit, little-endian, init-value=0, base-type=uint8, implementation-data-type=DT_BCM_KeyPosition_ON2B, update-indication-bit-position=-1, to MVCU
          signal BCM_NM_PNC_ON_3Ch_Sts: start 73, 1 bit, little-endian, init-value=0, base-type=uint8, implementation-data-type=DT_BCM_NM_PNC_ON_3Ch_Sts, update-indication-bit-position=-1, to MVCU
          signal BCM_HighVoltageReq: start 114, 2 bit, little-endian, init-value=0, base-type=uint8, implementation-data-type=DT_BCM_HighVoltageReq, update-indication-bit-position=-1, to MVCU
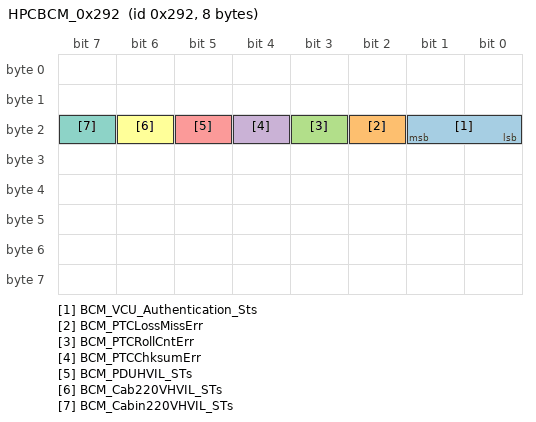
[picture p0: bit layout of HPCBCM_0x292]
      frame HPCBCM_0x292: id 0x292, to MVCU, frame-length=8, can-addressing-mode=STANDARD, can-fd-frame-support=true, can-frame-rx-behavior=CAN-FD
        carries pdu HPCBCM_0x292: packing-byte-order=little-endian, start-position=0, update-indication-bit-position=-1
        pdu HPCBCM_0x292: length=8, transmission-mode-false-timing=cyclic-timing={time-offset=0.0, time-period=0.02}, transmission-mode-true-timing=cyclic-timing={time-offset=0.0, time-period=0.02}
          transmission-mode-conditions:
            {data-filter={data-filter-type=ALWAYS, max=3, min=0, offset=0}, i-signal-in-i-pdu=BCM_VCU_Authentication_Sts}
            {data-filter={data-filter-type=ALWAYS, max=1, min=0, offset=0}, i-signal-in-i-pdu=BCM_PTCLossMissErr}
            {data-filter={data-filter-type=ALWAYS, max=1, min=0, offset=0}, i-signal-in-i-pdu=BCM_PTCRollCntErr}
            {data-filter={data-filter-type=ALWAYS, max=1, min=0, offset=0}, i-signal-in-i-pdu=BCM_PTCChksumErr}
            {data-filter={data-filter-type=ALWAYS, max=1, min=0, offset=0}, i-signal-in-i-pdu=BCM_PDUHVIL_STs}
            {data-filter={data-filter-type=ALWAYS, max=1, min=0, offset=0}, i-signal-in-i-pdu=BCM_Cab220VHVIL_STs}
            {data-filter={data-filter-type=ALWAYS, max=1, min=0, offset=0}, i-signal-in-i-pdu=BCM_Cabin220VHVIL_STs}
          signal BCM_VCU_Authentication_Sts: start 16, 2 bit, little-endian, init-value=0, base-type=uint8, implementation-data-type=DT_BCM_VCU_Authentication_Sts, update-indication-bit-position=-1, to MVCU
          signal BCM_PTCLossMissErr: start 18, 1 bit, little-endian, init-value=0, base-type=uint8, implementation-data-type=DT_BCM_PTCLossMissErr, update-indication-bit-position=-1, to MVCU
          signal BCM_PTCRollCntErr: start 19, 1 bit, little-endian, init-value=0, base-type=uint8, implementation-data-type=DT_BCM_PTCRollCntErr, update-indication-bit-position=-1, to MVCU
          signal BCM_PTCChksumErr: start 20, 1 bit, little-endian, init-value=0, base-type=uint8, implementation-data-type=DT_BCM_PTCChksumErr, update-indication-bit-position=-1, to MVCU
          signal BCM_PDUHVIL_STs: start 21, 1 bit, little-endian, init-value=0, base-type=uint8, implementation-data-type=DT_BCM_PDUHVIL_STs, update-indication-bit-position=-1, to MVCU
          signal BCM_Cab220VHVIL_STs: start 22, 1 bit, little-endian, init-value=0, base-type=uint8, implementation-data-type=DT_BCM_Cab220VHVIL_STs, update-indication-bit-position=-1, to MVCU
          signal BCM_Cabin220VHVIL_STs: start 23, 1 bit, little-endian, init-value=0, base-type=uint8, implementation-data-type=DT_BCM_Cabin220VHVIL_STs, update-indication-bit-position=-1, to MVCU
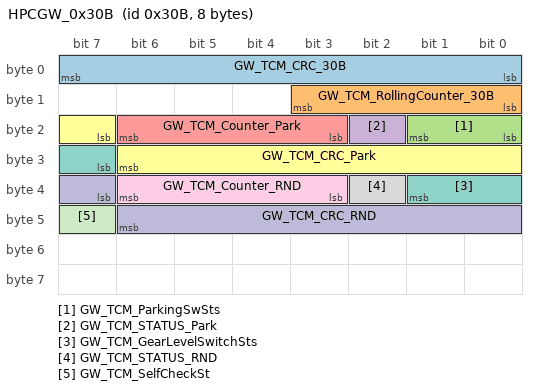
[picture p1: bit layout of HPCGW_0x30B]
      frame HPCGW_0x30B: id 0x30B, to MVCU, frame-length=8, can-addressing-mode=STANDARD, can-fd-frame-support=true, can-frame-rx-behavior=CAN-FD
        carries pdu HPCGW_0x30B: packing-byte-order=little-endian, start-position=0, update-indication-bit-position=-1
        pdu HPCGW_0x30B: length=8, transmission-mode-false-timing=cyclic-timing={time-offset=0.0, time-period=0.02}, transmission-mode-true-timing=cyclic-timing={time-offset=0.0, time-period=0.02}
          transmission-mode-conditions:
            {data-filter={data-filter-type=ALWAYS, max=255, min=0, offset=0}, i-signal-in-i-pdu=GW_TCM_CRC_30B}
            {data-filter={data-filter-type=ALWAYS, max=15, min=0, offset=0}, i-signal-in-i-pdu=GW_TCM_RollingCounter_30B}
            {data-filter={data-filter-type=ALWAYS, max=3, min=0, offset=0}, i-signal-in-i-pdu=GW_TCM_ParkingSwSts}
            {data-filter={data-filter-type=ALWAYS, max=1, min=0, offset=0}, i-signal-in-i-pdu=GW_TCM_STATUS_Park}
            {data-filter={data-filter-type=ALWAYS, max=15, min=0, offset=0}, i-signal-in-i-pdu=GW_TCM_Counter_Park}
            {data-filter={data-filter-type=ALWAYS, max=255, min=0, offset=0}, i-signal-in-i-pdu=GW_TCM_CRC_Park}
            {data-filter={data-filter-type=ALWAYS, max=7, min=0, offset=0}, i-signal-in-i-pdu=GW_TCM_GearLevelSwitchSts}
            {data-filter={data-filter-type=ALWAYS, max=1, min=0, offset=0}, i-signal-in-i-pdu=GW_TCM_STATUS_RND}
            {data-filter={data-filter-type=ALWAYS, max=15, min=0, offset=0}, i-signal-in-i-pdu=GW_TCM_Counter_RND}
            {data-filter={data-filter-type=ALWAYS, max=255, min=0, offset=0}, i-signal-in-i-pdu=GW_TCM_CRC_RND}
            {data-filter={data-filter-type=ALWAYS, max=1, min=0, offset=0}, i-signal-in-i-pdu=GW_TCM_SelfCheckSt}
          signal GW_TCM_CRC_30B: start 0, 8 bit, little-endian, init-value=0, base-type=uint8, implementation-data-type=DT_GW_TCM_CRC_30B, update-indication-bit-position=-1, to MVCU
          signal GW_TCM_RollingCounter_30B: start 8, 4 bit, little-endian, init-value=0, base-type=uint8, implementation-data-type=DT_GW_TCM_RollingCounter_30B, update-indication-bit-position=-1, to MVCU
          signal GW_TCM_ParkingSwSts: start 16, 2 bit, little-endian, init-value=0, base-type=uint8, implementation-data-type=DT_GW_TCM_ParkingSwSts, update-indication-bit-position=-1, to MVCU
          signal GW_TCM_STATUS_Park: start 18, 1 bit, little-endian, init-value=0, base-type=uint8, implementation-data-type=DT_GW_TCM_STATUS_Park, update-indication-bit-position=-1, to MVCU
          signal GW_TCM_Counter_Park: start 19, 4 bit, little-endian, init-value=0, base-type=uint8, implementation-data-type=DT_GW_TCM_Counter_Park, update-indication-bit-position=-1, to MVCU
          signal GW_TCM_CRC_Park: start 23, 8 bit, little-endian, init-value=0, base-type=uint8, implementation-data-type=DT_GW_TCM_CRC_Park, update-indication-bit-position=-1, to MVCU
          signal GW_TCM_GearLevelSwitchSts: start 31, 3 bit, little-endian, init-value=0, base-type=uint8, implementation-data-type=DT_GW_TCM_GearLevelSwitchSts, update-indication-bit-position=-1, to MVCU
          signal GW_TCM_STATUS_RND: start 34, 1 bit, little-endian, init-value=0, base-type=uint8, implementation-data-type=DT_GW_TCM_STATUS_RND, update-indication-bit-position=-1, to MVCU
          signal GW_TCM_Counter_RND: start 35, 4 bit, little-endian, init-value=0, base-type=uint8, implementation-data-type=DT_GW_TCM_Counter_RND, update-indication-bit-position=-1, to MVCU
          signal GW_TCM_CRC_RND: start 39, 8 bit, little-endian, init-value=0, base-type=uint8, implementation-data-type=DT_GW_TCM_CRC_RND, update-indication-bit-position=-1, to MVCU
          signal GW_TCM_SelfCheckSt: start 47, 1 bit, little-endian, init-value=0, base-type=uint8, implementation-data-type=DT_GW_TCM_SelfCheckSt, update-indication-bit-position=-1, to MVCU
      frame BMS_0x1A1: id 0x1A1, to MVCU, frame-length=32, can-addressing-mode=STANDARD, can-fd-frame-support=true, can-frame-rx-behavior=CAN-FD
        carries pdu BMS_0x1A1: packing-byte-order=little-endian, start-position=0, update-indication-bit-position=-1
        pdu BMS_0x1A1: length=32, transmission-mode-false-timing=cyclic-timing={time-offset=0.0, time-period=0.01}, transmission-mode-true-timing=cyclic-timing={time-offset=0.0, time-period=0.01}
          transmission-mode-conditions:
            {data-filter={data-filter-type=ALWAYS, max=255, min=0, offset=0}, i-signal-in-i-pdu=BMS_CRC_1A1}
            {data-filter={data-filter-type=ALWAYS, max=15, min=0, offset=0}, i-signal-in-i-pdu=BMS_RollingCounter_1A1}
            {data-filter={data-filter-type=ALWAYS, max=3, min=0, offset=0}, i-signal-in-i-pdu=BMS_Warning_Level}
            {data-filter={data-filter-type=ALWAYS, max=2, min=0, offset=0}, i-signal-in-i-pdu=BMS_SelfCheck}
            {data-filter={data-filter-type=ALWAYS, max=7, min=0, offset=0}, i-signal-in-i-pdu=BMS_BattChargerSts}
            {data-filter={data-filter-type=ALWAYS, max=1, min=0, offset=0}, i-signal-in-i-pdu=BMS_RHighVolSts}
            {data-filter={data-filter-type=ALWAYS, max=1, min=0, offset=0}, i-signal-in-i-pdu=BMS_RPreChargeRelayFB}
            {data-filter={data-filter-type=ALWAYS, max=1, min=0, offset=0}, i-signal-in-i-pdu=BMS_RPositiveRelayFB}
            {data-filter={data-filter-type=ALWAYS, max=1, min=0, offset=0}, i-signal-in-i-pdu=BMS_RNegativeRelayFB}
            {data-filter={data-filter-type=ALWAYS, max=1, min=0, offset=0}, i-signal-in-i-pdu=BMS_RPositiveRelay_F}
            {data-filter={data-filter-type=ALWAYS, max=1, min=0, offset=0}, i-signal-in-i-pdu=BMS_RNegativeRelay_F}
            {data-filter={data-filter-type=ALWAYS, max=3, min=0, offset=0}, i-signal-in-i-pdu=BMS_RPreChargeFinishSts}
            {data-filter={data-filter-type=ALWAYS, max=1, min=0, offset=0}, i-signal-in-i-pdu=BMS_MCUMHVILSts}
            {data-filter={data-filter-type=ALWAYS, max=1, min=0, offset=0}, i-signal-in-i-pdu=BMS_ACPTCHVILSts}
            {data-filter={data-filter-type=ALWAYS, max=1, min=0, offset=0}, i-signal-in-i-pdu=BMS_PTCHVILSts}
            {data-filter={data-filter-type=ALWAYS, max=1, min=0, offset=0}, i-signal-in-i-pdu=BMS_CCMHVILSts}
            {data-filter={data-filter-type=ALWAYS, max=1, min=0, offset=0}, i-signal-in-i-pdu=BMS_CDUHVILSts}
            {data-filter={data-filter-type=ALWAYS, max=1, min=0, offset=0}, i-signal-in-i-pdu=BMS_DCChgHVILSts}
            {data-filter={data-filter-type=ALWAYS, max=1, min=0, offset=0}, i-signal-in-i-pdu=BMS_MCUSHVILSts}
            {data-filter={data-filter-type=ALWAYS, max=1, min=0, offset=0}, i-signal-in-i-pdu=BMS_HVOffSts}
            {data-filter={data-filter-type=ALWAYS, max=3, min=0, offset=0}, i-signal-in-i-pdu=BMS_SeriousWarning_Level}
            {data-filter={data-filter-type=ALWAYS, max=1, min=0, offset=0}, i-signal-in-i-pdu=BMS_DCChgRelayCloseReq}
            {data-filter={data-filter-type=ALWAYS, max=1, min=0, offset=0}, i-signal-in-i-pdu=BMS_DCChgRelayFB}
            {data-filter={data-filter-type=ALWAYS, max=63, min=0, offset=0}, i-signal-in-i-pdu=BMS_ChgStopReason}
            {data-filter={data-filter-type=ALWAYS, max=1, min=0, offset=0}, i-signal-in-i-pdu=BMS_GCUHVILSts}
            {data-filter={data-filter-type=ALWAYS, max=1, min=0, offset=0}, i-signal-in-i-pdu=BMS_MILlampReq}
            {data-filter={data-filter-type=ALWAYS, max=1, min=0, offset=0}, i-signal-in-i-pdu=BMS_IsoRessistanceSts}
            {data-filter={data-filter-type=ALWAYS, max=1, min=0, offset=0}, i-signal-in-i-pdu=BMS_Integrity_Check}
            {data-filter={data-filter-type=NEW-IS-WITHIN, max=10000, min=0, offset=0}, i-signal-in-i-pdu=BMS_BattVolt}
            {data-filter={data-filter-type=NEW-IS-WITHIN, max=30000, min=0}, i-signal-in-i-pdu=BMS_BattCurr}
            {data-filter={data-filter-type=NEW-IS-WITHIN, max=5000, min=0, offset=0}, i-signal-in-i-pdu=BMS_BatDyn_Dchgpwr}
            {data-filter={data-filter-type=NEW-IS-WITHIN, max=5000, min=0, offset=0}, i-signal-in-i-pdu=BMS_BatDyn_Chgpwr}
            {data-filter={data-filter-type=ALWAYS, max=3, min=0, offset=0}, i-signal-in-i-pdu=BMS_Precharge_CoolingSts}
          signal BMS_CRC_1A1: start 0, 8 bit, little-endian, init-value=0, base-type=uint8, implementation-data-type=DT_BMS_CRC_1A1, update-indication-bit-position=-1, to MVCU
          signal BMS_RollingCounter_1A1: start 8, 4 bit, little-endian, init-value=0, base-type=uint8, implementation-data-type=DT_BMS_RollingCounter_1A1, update-indication-bit-position=-1, to MVCU
          signal BMS_Warning_Level: start 16, 2 bit, little-endian, init-value=0, base-type=uint8, implementation-data-type=DT_BMS_Warning_Level, update-indication-bit-position=-1, to MVCU
          signal BMS_SelfCheck: start 18, 2 bit, little-endian, init-value=0, base-type=uint8, implementation-data-type=DT_BMS_SelfCheck, update-indication-bit-position=-1, to MVCU
          signal BMS_BattChargerSts: start 20, 3 bit, little-endian, init-value=0, base-type=uint8, implementation-data-type=DT_BMS_BattChargerSts, update-indication-bit-position=-1, to MVCU
          signal BMS_RHighVolSts: start 24, 1 bit, little-endian, init-value=0, base-type=uint8, implementation-data-type=DT_BMS_RHighVolSts, update-indication-bit-position=-1, to MVCU
          signal BMS_RPreChargeRelayFB: start 25, 1 bit, little-endian, init-value=0, base-type=uint8, implementation-data-type=DT_BMS_RPreChargeRelayFB, update-indication-bit-position=-1, to MVCU
          signal BMS_RPositiveRelayFB: start 26, 1 bit, little-endian, init-value=0, base-type=uint8, implementation-data-type=DT_BMS_RPositiveRelayFB, update-indication-bit-position=-1, to MVCU
          signal BMS_RNegativeRelayFB: start 27, 1 bit, little-endian, init-value=0, base-type=uint8, implementation-data-type=DT_BMS_RNegativeRelayFB, update-indication-bit-position=-1, to MVCU
          signal BMS_RPositiveRelay_F: start 28, 1 bit, little-endian, init-value=0, base-type=uint8, implementation-data-type=DT_BMS_RPositiveRelay_F, update-indication-bit-position=-1, to MVCU
          signal BMS_RNegativeRelay_F: start 29, 1 bit, little-endian, init-value=0, base-type=uint8, implementation-data-type=DT_BMS_RNegativeRelay_F, update-indication-bit-position=-1, to MVCU
          signal BMS_RPreChargeFinishSts: start 30, 2 bit, little-endian, init-value=0, base-type=uint8, implementation-data-type=DT_BMS_RPreChargeFinishSts, update-indication-bit-position=-1, to MVCU
          signal BMS_MCUMHVILSts: start 40, 1 bit, little-endian, init-value=0, base-type=uint8, implementation-data-type=DT_BMS_MCUMHVILSts, update-indication-bit-position=-1, to MVCU
          signal BMS_ACPTCHVILSts: start 41, 1 bit, little-endian, init-value=0, base-type=uint8, implementation-data-type=DT_BMS_ACPTCHVILSts, update-indication-bit-position=-1, to MVCU
          signal BMS_PTCHVILSts: start 42, 1 bit, little-endian, init-value=0, base-type=uint8, implementation-data-type=DT_BMS_PTCHVILSts, update-indication-bit-position=-1, to MVCU
          signal BMS_CCMHVILSts: start 43, 1 bit, little-endian, init-value=0, base-type=uint8, implementation-data-type=DT_BMS_CCMHVILSts, update-indication-bit-position=-1, to MVCU
          signal BMS_CDUHVILSts: start 44, 1 bit, little-endian, init-value=0, base-type=uint8, implementation-data-type=DT_BMS_CDUHVILSts, update-indication-bit-position=-1, to MVCU
          signal BMS_DCChgHVILSts: start 45, 1 bit, little-endian, init-value=0, base-type=uint8, implementation-data-type=DT_BMS_DCChgHVILSts, update-indication-bit-position=-1, to MVCU
          signal BMS_MCUSHVILSts: start 46, 1 bit, little-endian, init-value=0, base-type=uint8, implementation-data-type=DT_BMS_MCUSHVILSts, update-indication-bit-position=-1, to MVCU
          signal BMS_HVOffSts: start 47, 1 bit, little-endian, init-value=0, base-type=uint8, implementation-data-type=DT_BMS_HVOffSts, update-indication-bit-position=-1, to MVCU
          signal BMS_SeriousWarning_Level: start 48, 2 bit, little-endian, init-value=0, base-type=uint8, implementation-data-type=DT_BMS_SeriousWarning_Level, update-indication-bit-position=-1, to MVCU
          signal BMS_DCChgRelayCloseReq: start 50, 1 bit, little-endian, init-value=0, base-type=uint8, implementation-data-type=DT_BMS_DCChgRelayCloseReq, update-indication-bit-position=-1, to MVCU
          signal BMS_DCChgRelayFB: start 56, 1 bit, little-endian, init-value=0, base-type=uint8, implementation-data-type=DT_BMS_DCChgRelayFB, update-indication-bit-position=-1, to MVCU
          signal BMS_ChgStopReason: start 57, 6 bit, little-endian, init-value=0, base-type=uint8, implementation-data-type=DT_BMS_ChgStopReason, update-indication-bit-position=-1, to MVCU
          signal BMS_GCUHVILSts: start 65, 1 bit, little-endian, init-value=0, base-type=uint8, implementation-data-type=DT_BMS_GCUHVILSts, update-indication-bit-position=-1, to MVCU
          signal BMS_MILlampReq: start 66, 1 bit, little-endian, init-value=0, base-type=uint8, implementation-data-type=DT_BMS_MILlampReq, update-indication-bit-position=-1, to MVCU
          signal BMS_IsoRessistanceSts: start 67, 1 bit, little-endian, init-value=0, base-type=uint8, implementation-data-type=DT_BMS_IsoRessistanceSts, update-indication-bit-position=-1, to MVCU
          signal BMS_Integrity_Check: start 70, 1 bit, little-endian, init-value=0, base-type=uint8, implementation-data-type=DT_BMS_Integrity_Check, update-indication-bit-position=-1, to MVCU
          signal BMS_BattVolt: start 72, 16 bit, little-endian, init-value=0, base-type=uint16, implementation-data-type=DT_BMS_BattVolt, update-indication-bit-position=-1, to MVCU
          signal BMS_BattCurr: start 88, 16 bit, little-endian, init-value=0, base-type=uint16, implementation-data-type=DT_BMS_BattCurr, update-indication-bit-position=-1, to MVCU
          signal BMS_BatDyn_Dchgpwr: start 104, 13 bit, little-endian, init-value=0, base-type=uint16, implementation-data-type=DT_BMS_BatDyn_Dchgpwr, update-indication-bit-position=-1, to MVCU
          signal BMS_BatDyn_Chgpwr: start 120, 13 bit, little-endian, init-value=0, base-type=uint16, implementation-data-type=DT_BMS_BatDyn_Chgpwr, update-indication-bit-position=-1, to MVCU
          signal BMS_Precharge_CoolingSts: start 254, 2 bit, little-endian, init-value=0, base-type=uint8, implementation-data-type=DT_BMS_Precharge_CoolingSts, update-indication-bit-position=-1, to MVCU
      frame MCUS_0xDB: id 0xDB, to MVCU, frame-length=32, can-addressing-mode=STANDARD, can-fd-frame-support=true, can-frame-rx-behavior=CAN-FD
        carries pdu MCUS_0xDB: packing-byte-order=little-endian, start-position=0, update-indication-bit-position=-1
        pdu MCUS_0xDB: length=32, transmission-mode-false-timing=cyclic-timing={time-offset=0.0, time-period=0.01}, transmission-mode-true-timing=cyclic-timing={time-offset=0.0, time-period=0.01}
          transmission-mode-conditions:
            {data-filter={data-filter-type=ALWAYS, max=255, min=0, offset=0}, i-signal-in-i-pdu=MCUS_CRC_DB}
            {data-filter={data-filter-type=ALWAYS, max=1023, min=0, offset=0}, i-signal-in-i-pdu=MCUS_Clutch_2_Fault}
            {data-filter={data-filter-type=ALWAYS, max=1023, min=0, offset=0}, i-signal-in-i-pdu=MCUS_Clutch_1_Fault}
            {data-filter={data-filter-type=ALWAYS, max=3, min=0, offset=0}, i-signal-in-i-pdu=MCUS_Clutch_2_WarningLevel}
            {data-filter={data-filter-type=ALWAYS, max=3, min=0, offset=0}, i-signal-in-i-pdu=MCUS_Clutch_1_WarningLevel}
            {data-filter={data-filter-type=ALWAYS, max=7, min=0, offset=0}, i-signal-in-i-pdu=MCUS_Clutch_2_Pos}
            {data-filter={data-filter-type=ALWAYS, max=7, min=0, offset=0}, i-signal-in-i-pdu=MCUS_Clutch_1_Pos}
            {data-filter={data-filter-type=ALWAYS, max=15, min=0, offset=0}, i-signal-in-i-pdu=MCUS_RollingCounter_DB}
            {data-filter={data-filter-type=ALWAYS, max=3, min=0, offset=0}, i-signal-in-i-pdu=MCUS_WarningLevel}
            {data-filter={data-filter-type=ALWAYS, max=3, min=0, offset=0}, i-signal-in-i-pdu=MCUS_SelfCheckSts}
            {data-filter={data-filter-type=ALWAYS, max=3, min=0, offset=0}, i-signal-in-i-pdu=MCUS_DrvMotorWorkSts}
            {data-filter={data-filter-type=ALWAYS, max=1, min=0, offset=0}, i-signal-in-i-pdu=MCUS_PowerReduceSts}
            {data-filter={data-filter-type=ALWAYS, max=1, min=0, offset=0}, i-signal-in-i-pdu=MCUS_SystemError}
            {data-filter={data-filter-type=ALWAYS, max=1, min=0, offset=0}, i-signal-in-i-pdu=MCUS_LVSystemError}
            {data-filter={data-filter-type=ALWAYS, max=1, min=0, offset=0}, i-signal-in-i-pdu=MCUS_MotorTempAlarm}
            {data-filter={data-filter-type=ALWAYS, max=1, min=0, offset=0}, i-signal-in-i-pdu=MCUS_HVSystemError}
            {data-filter={data-filter-type=ALWAYS, max=3, min=0, offset=0}, i-signal-in-i-pdu=MCUS_SeriousWarning_Level}
            {data-filter={data-filter-type=ALWAYS, max=1, min=0, offset=0}, i-signal-in-i-pdu=MCUS_CtrlModeVD}
            {data-filter={data-filter-type=ALWAYS, max=10, min=0, offset=0}, i-signal-in-i-pdu=MCUS_WaterPumpLevlReq}
            {data-filter={data-filter-type=ALWAYS, max=250, min=0, offset=0}, i-signal-in-i-pdu=MCUS_MotorTemp}
            {data-filter={data-filter-type=ALWAYS, max=250, min=0, offset=0}, i-signal-in-i-pdu=MCUS_IGBTTemp}
            {data-filter={data-filter-type=ALWAYS, max=250, min=0, offset=0}, i-signal-in-i-pdu=MCUS_InletTemp}
            {data-filter={data-filter-type=NEW-IS-WITHIN, max=47000, min=0}, i-signal-in-i-pdu=MCUS_DrvMotorRPM}
            {data-filter={data-filter-type=NEW-IS-WITHIN, max=10000, min=0}, i-signal-in-i-pdu=MCUS_ActualTorqueFB}
            {data-filter={data-filter-type=ALWAYS, max=1, min=0, offset=0}, i-signal-in-i-pdu=MCUS_HWRdcFault}
            {data-filter={data-filter-type=ALWAYS, max=1, min=0, offset=0}, i-signal-in-i-pdu=MCUS_HighVoltPowerOffReq}
            {data-filter={data-filter-type=ALWAYS, max=1, min=0, offset=0}, i-signal-in-i-pdu=MCUS_HVILSts}
            {data-filter={data-filter-type=ALWAYS, max=3, min=0, offset=0}, i-signal-in-i-pdu=MCUS_DragSts}
            {data-filter={data-filter-type=ALWAYS, max=1, min=0, offset=0}, i-signal-in-i-pdu=MCUS_CtrlMode}
            {data-filter={data-filter-type=ALWAYS, max=1, min=0, offset=0}, i-signal-in-i-pdu=MCUS_MILlampReq}
            {data-filter={data-filter-type=ALWAYS, max=1, min=0, offset=0}, i-signal-in-i-pdu=MCUS_DrvMotorRPMVD}
            {data-filter={data-filter-type=ALWAYS, max=1, min=0, offset=0}, i-signal-in-i-pdu=MCUS_ActualTorqueFBVD}
            {data-filter={data-filter-type=NEW-IS-WITHIN, max=10000, min=0}, i-signal-in-i-pdu=MCUS_MaxTorqueAllow}
            {data-filter={data-filter-type=NEW-IS-WITHIN, max=34000, min=0}, i-signal-in-i-pdu=MCUS_MaxSpeedAllow}
            {data-filter={data-filter-type=ALWAYS, max=3, min=0, offset=0}, i-signal-in-i-pdu=MCUS_ActiveReleaseSts}
            {data-filter={data-filter-type=NEW-IS-WITHIN, max=10000, min=0}, i-signal-in-i-pdu=MCUS_MinTorqueAllow}
            {data-filter={data-filter-type=NEW-IS-WITHIN, max=10000, min=0, offset=0}, i-signal-in-i-pdu=MCUS_MainWireVolt}
            {data-filter={data-filter-type=NEW-IS-WITHIN, max=20000, min=0}, i-signal-in-i-pdu=MCUS_MainWireCurr}
            {data-filter={data-filter-type=ALWAYS, max=7, min=0, offset=0}, i-signal-in-i-pdu=MCUS_Clutch_Pos}
            {data-filter={data-filter-type=ALWAYS, max=15, min=0, offset=0}, i-signal-in-i-pdu=MCUS_Clutch_Fault}
            {data-filter={data-filter-type=ALWAYS, max=1, min=0, offset=0}, i-signal-in-i-pdu=MCUS_TMS_FrMotSelfHeatEnSts}
            {data-filter={data-filter-type=ALWAYS, max=7, min=0, offset=0}, i-signal-in-i-pdu=MCUS_TMS_FrMotSelfHeatLvlFb}
            {data-filter={data-filter-type=ALWAYS, max=31, min=0, offset=0}, i-signal-in-i-pdu=MCUS_HeatPwrAval}
          signal MCUS_CRC_DB: start 0, 8 bit, little-endian, init-value=0, base-type=uint8, implementation-data-type=DT_MCUS_CRC_DB, update-indication-bit-position=-1, to MVCU
          signal MCUS_Clutch_2_Fault: start 220, 10 bit, little-endian, init-value=0, base-type=uint16, implementation-data-type=DT_MCUS_Clutch_2_Fault, update-indication-bit-position=-1, to MVCU
          signal MCUS_Clutch_1_Fault: start 210, 10 bit, little-endian, init-value=0, base-type=uint16, implementation-data-type=DT_MCUS_Clutch_1_Fault, update-indication-bit-position=-1, to MVCU
          signal MCUS_Clutch_2_WarningLevel: start 208, 2 bit, little-endian, init-value=0, base-type=uint8, implementation-data-type=DT_MCUS_Clutch_2_WarningLevel, update-indication-bit-position=-1, to MVCU
          signal MCUS_Clutch_1_WarningLevel: start 206, 2 bit, little-endian, init-value=0, base-type=uint8, implementation-data-type=DT_MCUS_Clutch_1_WarningLevel, update-indication-bit-position=-1, to MVCU
          signal MCUS_Clutch_2_Pos: start 203, 3 bit, little-endian, init-value=0, base-type=uint8, implementation-data-type=DT_MCUS_Clutch_2_Pos, update-indication-bit-position=-1, to MVCU
          signal MCUS_Clutch_1_Pos: start 200, 3 bit, little-endian, init-value=0, base-type=uint8, implementation-data-type=DT_MCUS_Clutch_1_Pos, update-indication-bit-position=-1, to MVCU
          signal MCUS_RollingCounter_DB: start 8, 4 bit, little-endian, init-value=0, base-type=uint8, implementation-data-type=DT_MCUS_RollingCounter_DB, update-indication-bit-position=-1, to MVCU
          signal MCUS_WarningLevel: start 16, 2 bit, little-endian, init-value=0, base-type=uint8, implementation-data-type=DT_MCUS_WarningLevel, update-indication-bit-position=-1, to MVCU
          signal MCUS_SelfCheckSts: start 18, 2 bit, little-endian, init-value=0, base-type=uint8, implementation-data-type=DT_MCUS_SelfCheckSts, update-indication-bit-position=-1, to MVCU
          signal MCUS_DrvMotorWorkSts: start 20, 2 bit, little-endian, init-value=0, base-type=uint8, implementation-data-type=DT_MCUS_DrvMotorWorkSts, update-indication-bit-position=-1, to MVCU
          signal MCUS_PowerReduceSts: start 22, 1 bit, little-endian, init-value=0, base-type=uint8, implementation-data-type=DT_MCUS_PowerReduceSts, update-indication-bit-position=-1, to MVCU
          signal MCUS_SystemError: start 23, 1 bit, little-endian, init-value=0, base-type=uint8, implementation-data-type=DT_MCUS_SystemError, update-indication-bit-position=-1, to MVCU
          signal MCUS_LVSystemError: start 57, 1 bit, little-endian, init-value=0, base-type=uint8, implementation-data-type=DT_MCUS_LVSystemError, update-indication-bit-position=-1, to MVCU
          signal MCUS_MotorTempAlarm: start 63, 1 bit, little-endian, init-value=0, base-type=uint8, implementation-data-type=DT_MCUS_MotorTempAlarm, update-indication-bit-position=-1, to MVCU
          signal MCUS_HVSystemError: start 64, 1 bit, little-endian, init-value=0, base-type=uint8, implementation-data-type=DT_MCUS_HVSystemError, update-indication-bit-position=-1, to MVCU
          signal MCUS_SeriousWarning_Level: start 66, 2 bit, little-endian, init-value=0, base-type=uint8, implementation-data-type=DT_MCUS_SeriousWarning_Level, update-indication-bit-position=-1, to MVCU
          signal MCUS_CtrlModeVD: start 70, 1 bit, little-endian, init-value=0, base-type=uint8, implementation-data-type=DT_MCUS_CtrlModeVD, update-indication-bit-position=-1, to MVCU
          signal MCUS_WaterPumpLevlReq: start 104, 4 bit, little-endian, init-value=0, base-type=uint8, implementation-data-type=DT_MCUS_WaterPumpLevlReq, update-indication-bit-position=-1, to MVCU
          signal MCUS_MotorTemp: start 144, 8 bit, little-endian, init-value=0, base-type=uint8, implementation-data-type=DT_MCUS_MotorTemp, update-indication-bit-position=-1, to MVCU
          signal MCUS_IGBTTemp: start 152, 8 bit, little-endian, init-value=0, base-type=uint8, implementation-data-type=DT_MCUS_IGBTTemp, update-indication-bit-position=-1, to MVCU
          signal MCUS_InletTemp: start 160, 8 bit, little-endian, init-value=0, base-type=uint8, implementation-data-type=DT_MCUS_InletTemp, update-indication-bit-position=-1, to MVCU
          signal MCUS_DrvMotorRPM: start 24, 16 bit, little-endian, init-value=0, base-type=uint16, implementation-data-type=DT_MCUS_DrvMotorRPM, update-indication-bit-position=-1, to MVCU
          signal MCUS_ActualTorqueFB: start 40, 16 bit, little-endian, init-value=0, base-type=uint16, implementation-data-type=DT_MCUS_ActualTorqueFB, update-indication-bit-position=-1, to MVCU
          signal MCUS_HWRdcFault: start 56, 1 bit, little-endian, init-value=0, base-type=uint8, implementation-data-type=DT_MCUS_HWRdcFault, update-indication-bit-position=-1, to MVCU
          signal MCUS_HighVoltPowerOffReq: start 58, 1 bit, little-endian, init-value=0, base-type=uint8, implementation-data-type=DT_MCUS_HighVoltPowerOffReq, update-indication-bit-position=-1, to MVCU
          signal MCUS_HVILSts: start 59, 1 bit, little-endian, init-value=0, base-type=uint8, implementation-data-type=DT_MCUS_HVILSts, update-indication-bit-position=-1, to MVCU
          signal MCUS_DragSts: start 60, 2 bit, little-endian, init-value=0, base-type=uint8, implementation-data-type=DT_MCUS_DragSts, update-indication-bit-position=-1, to MVCU
          signal MCUS_CtrlMode: start 62, 1 bit, little-endian, init-value=0, base-type=uint8, implementation-data-type=DT_MCUS_CtrlMode, update-indication-bit-position=-1, to MVCU
          signal MCUS_MILlampReq: start 65, 1 bit, little-endian, init-value=0, base-type=uint8, implementation-data-type=DT_MCUS_MILlampReq, update-indication-bit-position=-1, to MVCU
          signal MCUS_DrvMotorRPMVD: start 68, 1 bit, little-endian, init-value=0, base-type=uint8, implementation-data-type=DT_MCUS_DrvMotorRPMVD, update-indication-bit-position=-1, to MVCU
          signal MCUS_ActualTorqueFBVD: start 69, 1 bit, little-endian, init-value=0, base-type=uint8, implementation-data-type=DT_MCUS_ActualTorqueFBVD, update-indication-bit-position=-1, to MVCU
          signal MCUS_MaxTorqueAllow: start 72, 16 bit, little-endian, init-value=0, base-type=uint16, implementation-data-type=DT_MCUS_MaxTorqueAllow, update-indication-bit-position=-1, to MVCU
          signal MCUS_MaxSpeedAllow: start 88, 16 bit, little-endian, init-value=0, base-type=uint16, implementation-data-type=DT_MCUS_MaxSpeedAllow, update-indication-bit-position=-1, to MVCU
          signal MCUS_ActiveReleaseSts: start 108, 2 bit, little-endian, init-value=0, base-type=uint8, implementation-data-type=DT_MCUS_ActiveReleaseSts, update-indication-bit-position=-1, to MVCU
          signal MCUS_MinTorqueAllow: start 112, 16 bit, little-endian, init-value=0, base-type=uint16, implementation-data-type=DT_MCUS_MinTorqueAllow, update-indication-bit-position=-1, to MVCU
          signal MCUS_MainWireVolt: start 128, 16 bit, little-endian, init-value=0, base-type=uint16, implementation-data-type=DT_MCUS_MainWireVolt, update-indication-bit-position=-1, to MVCU
          signal MCUS_MainWireCurr: start 168, 16 bit, little-endian, init-value=0, base-type=uint16, implementation-data-type=DT_MCUS_MainWireCurr, update-indication-bit-position=-1, to MVCU
          signal MCUS_Clutch_Pos: start 184, 3 bit, little-endian, init-value=0, base-type=uint8, implementation-data-type=DT_MCUS_Clutch_Pos, update-indication-bit-position=-1, to MVCU
          signal MCUS_Clutch_Fault: start 187, 4 bit, little-endian, init-value=0, base-type=uint8, implementation-data-type=DT_MCUS_Clutch_Fault, update-indication-bit-position=-1, to MVCU
          signal MCUS_TMS_FrMotSelfHeatEnSts: start 191, 1 bit, little-endian, init-value=0, base-type=uint8, implementation-data-type=DT_MCUS_TMS_FrMotSelfHeatEnSts, update-indication-bit-position=-1, to MVCU
          signal MCUS_TMS_FrMotSelfHeatLvlFb: start 192, 3 bit, little-endian, init-value=0, base-type=uint8, implementation-data-type=DT_MCUS_TMS_FrMotSelfHeatLvlFb, update-indication-bit-position=-1, to MVCU
          signal MCUS_HeatPwrAval: start 195, 5 bit, little-endian, init-value=0, base-type=uint8, implementation-data-type=DT_MCUS_HeatPwrAval, update-indication-bit-position=-1, to MVCU
      frame XCP_Rx_603_VCU: id 0x603, to MVCU, frame-length=8, can-addressing-mode=STANDARD, can-fd-frame-support=true, can-frame-rx-behavior=CAN-20
        carries pdu XCP_Rx_603_VCU: packing-byte-order=big-endian, start-position=7, update-indication-bit-position=-1
        general purpose i pdu XCP_Rx_603_VCU: category=XCP, length=8
      frame ECM_0x5EC: id 0x5EC, to MVCU, frame-length=32, can-addressing-mode=STANDARD, can-fd-frame-support=true, can-frame-rx-behavior=CAN-FD
        carries pdu ECM_0x5EC: packing-byte-order=little-endian, start-position=0, update-indication-bit-position=-1
        pdu ECM_0x5EC: length=32, transmission-mode-condition{data-filter={data-filter-type=NEW-IS-WITHIN, max=65535, min=0, offset=0}, i-signal-in-i-pdu=ECM_EngineWorktime}, transmission-mode-false-timing=cyclic-timing={time-offset=0.0, time-period=1.0}, transmission-mode-true-timing=cyclic-timing={time-offset=0.0, time-period=1.0}
          signal ECM_EngineWorktime: start 32, 16 bit, little-endian, init-value=0, base-type=uint16, implementation-data-type=DT_ECM_EngineWorktime, update-indication-bit-position=-1, to MVCU
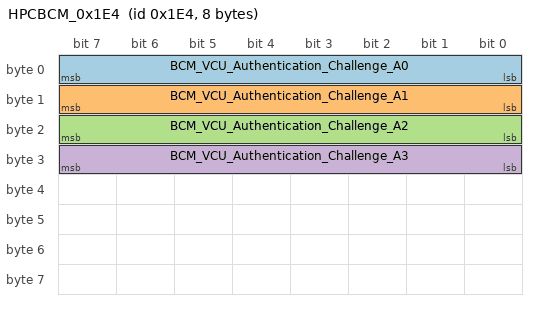
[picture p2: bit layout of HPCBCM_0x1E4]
      frame HPCBCM_0x1E4: id 0x1E4, to MVCU, frame-length=8, can-addressing-mode=STANDARD, can-fd-frame-support=true, can-frame-rx-behavior=CAN-FD
        carries pdu HPCBCM_0x1E4: packing-byte-order=little-endian, start-position=0, update-indication-bit-position=-1
        pdu HPCBCM_0x1E4: length=8
          transmission-mode-conditions:
            {data-filter={data-filter-type=ALWAYS, max=255, min=0, offset=0}, i-signal-in-i-pdu=BCM_VCU_Authentication_Challenge_A{0..3}}
          signal BCM_VCU_Authentication_Challenge_A0: start 0, 8 bit, little-endian, init-value=0, base-type=uint8, implementation-data-type=DT_BCM_VCU_Authentication_Challenge_A0, update-indication-bit-position=-1, to MVCU
          signal BCM_VCU_Authentication_Challenge_A1: start 8, 8 bit, little-endian, init-value=0, base-type=uint8, implementation-data-type=DT_BCM_VCU_Authentication_Challenge_A1, update-indication-bit-position=-1, to MVCU
          signal BCM_VCU_Authentication_Challenge_A2: start 16, 8 bit, little-endian, init-value=0, base-type=uint8, implementation-data-type=DT_BCM_VCU_Authentication_Challenge_A2, update-indication-bit-position=-1, to MVCU
          signal BCM_VCU_Authentication_Challenge_A3: start 24, 8 bit, little-endian, init-value=0, base-type=uint8, implementation-data-type=DT_BCM_VCU_Authentication_Challenge_A3, update-indication-bit-position=-1, to MVCU
      frame VCU_0x1: id 0x1, to MVCU, frame-length=32, can-addressing-mode=STANDARD, can-fd-frame-support=true, can-frame-rx-behavior=CAN-FD
        carries pdu VCU_0x1: packing-byte-order=little-endian, start-position=0, update-indication-bit-position=-1
        pdu VCU_0x1: length=32, transmission-mode-false-timing=cyclic-timing={time-offset=0.0, time-period=0.01}, transmission-mode-true-timing=cyclic-timing={time-offset=0.0, time-period=0.01}
          transmission-mode-conditions:
            {data-filter={data-filter-type=ALWAYS, max=255, min=0, offset=0}, i-signal-in-i-pdu=EOL_CRC_13B}
            {data-filter={data-filter-type=ALWAYS, max=15, min=0, offset=0}, i-signal-in-i-pdu=EOL_RollingCounter_13B}
            {data-filter={data-filter-type=ALWAYS, max=1, min=0, offset=0}, i-signal-in-i-pdu=EOL_VehicleSts}
            {data-filter={data-filter-type=ALWAYS, max=3, min=0, offset=0}, i-signal-in-i-pdu=EOL_GearLevelPosSts}
            {data-filter={data-filter-type=ALWAYS, max=1, min=0, offset=0}, i-signal-in-i-pdu=EOL_GearLeverValid}
            {data-filter={data-filter-type=ALWAYS, max=1, min=0, offset=0}, i-signal-in-i-pdu=EOL_AccPedalValid}
            {data-filter={data-filter-type=ALWAYS, max=254, min=0, offset=0}, i-signal-in-i-pdu=EOL_ThrottlePosition}
            {data-filter={data-filter-type=ALWAYS, max=1, min=0, offset=0}, i-signal-in-i-pdu=EOL_RMCUActiveReleaseCmd}
            {data-filter={data-filter-type=ALWAYS, max=1, min=0, offset=0}, i-signal-in-i-pdu=EOL_VehicleDirect}
            {data-filter={data-filter-type=ALWAYS, max=1, min=0, offset=0}, i-signal-in-i-pdu=EOL_SuppressJitterRMCURequest}
            {data-filter={data-filter-type=ALWAYS, max=1, min=0, offset=0}, i-signal-in-i-pdu=EOL_RDrvControlMode}
            {data-filter={data-filter-type=ALWAYS, max=254, min=0, offset=0}, i-signal-in-i-pdu=EOL_BrakePedalValue}
            {data-filter={data-filter-type=NEW-IS-WITHIN, max=510, min=0, offset=0}, i-signal-in-i-pdu=EOL_RMCUMaxDischargePower}
            {data-filter={data-filter-type=NEW-IS-WITHIN, max=510, min=0, offset=0}, i-signal-in-i-pdu=EOL_RMCUMaxChargePower}
            {data-filter={data-filter-type=NEW-IS-WITHIN, max=10000, min=0}, i-signal-in-i-pdu=EOL_RDrvRequestTorque}
            {data-filter={data-filter-type=NEW-IS-WITHIN, max=34000, min=0}, i-signal-in-i-pdu=EOL_RDrvRequesSpeed}
            {data-filter={data-filter-type=NEW-IS-WITHIN, max=10000, min=0}, i-signal-in-i-pdu=EOL_FDrvRequestTorque}
            {data-filter={data-filter-type=NEW-IS-WITHIN, max=34000, min=0}, i-signal-in-i-pdu=EOL_FDrvRequesSpeed}
            {data-filter={data-filter-type=ALWAYS, max=1, min=0, offset=0}, i-signal-in-i-pdu=EOL_FVehicleSts}
            {data-filter={data-filter-type=ALWAYS, max=1, min=0, offset=0}, i-signal-in-i-pdu=EOL_FDrvControlMode}
            {data-filter={data-filter-type=ALWAYS, max=3, min=0, offset=0}, i-signal-in-i-pdu=EOL_ON2BRelayReq}
            {data-filter={data-filter-type=ALWAYS, max=1, min=0, offset=0}, i-signal-in-i-pdu=EOL_VehicleDirectVD}
            {data-filter={data-filter-type=ALWAYS, max=1, min=0, offset=0}, i-signal-in-i-pdu=EOL_RDrvControlModeVD}
            {data-filter={data-filter-type=ALWAYS, max=1, min=0, offset=0}, i-signal-in-i-pdu=EOL_RDrvRequestTorqueVD}
            {data-filter={data-filter-type=ALWAYS, max=1, min=0, offset=0}, i-signal-in-i-pdu=EOL_RDrvRequesSpeedVD}
            {data-filter={data-filter-type=ALWAYS, max=1, min=0, offset=0}, i-signal-in-i-pdu=EOL_FDrvRequestTorqueVD}
            {data-filter={data-filter-type=ALWAYS, max=1, min=0, offset=0}, i-signal-in-i-pdu=EOL_FDrvRequesSpeedVD}
            {data-filter={data-filter-type=ALWAYS, max=1, min=0, offset=0}, i-signal-in-i-pdu=EOL_FDrvControlModeVD}
            {data-filter={data-filter-type=ALWAYS, max=100, min=0, offset=0}, i-signal-in-i-pdu=EOL_MCUMDampgLmtFactor}
            {data-filter={data-filter-type=ALWAYS, max=50, min=0, offset=0}, i-signal-in-i-pdu=EOL_MCUMMaxPosDampgTrq}
            {data-filter={data-filter-type=ALWAYS, max=50, min=0}, i-signal-in-i-pdu=EOL_MCUMMaxNegDampgTrq}
          signal EOL_CRC_13B: start 0, 8 bit, little-endian, init-value=0, base-type=uint8, implementation-data-type=DT_EOL_CRC_13B, update-indication-bit-position=-1, to MVCU
          signal EOL_RollingCounter_13B: start 8, 4 bit, little-endian, init-value=0, base-type=uint8, implementation-data-type=DT_EOL_RollingCounter_13B, update-indication-bit-position=-1, to MVCU
          signal EOL_VehicleSts: start 18, 1 bit, little-endian, init-value=0, base-type=uint8, implementation-data-type=DT_EOL_VehicleSts, update-indication-bit-position=-1, to MVCU
          signal EOL_GearLevelPosSts: start 19, 2 bit, little-endian, init-value=0, base-type=uint8, implementation-data-type=DT_EOL_GearLevelPosSts, update-indication-bit-position=-1, to MVCU
          signal EOL_GearLeverValid: start 21, 1 bit, little-endian, init-value=0, base-type=uint8, implementation-data-type=DT_EOL_GearLeverValid, update-indication-bit-position=-1, to MVCU
          signal EOL_AccPedalValid: start 23, 1 bit, little-endian, init-value=0, base-type=uint8, implementation-data-type=DT_EOL_AccPedalValid, update-indication-bit-position=-1, to MVCU
          signal EOL_ThrottlePosition: start 24, 8 bit, little-endian, init-value=0, base-type=uint8, implementation-data-type=DT_EOL_ThrottlePosition, update-indication-bit-position=-1, to MVCU
          signal EOL_RMCUActiveReleaseCmd: start 35, 1 bit, little-endian, init-value=0, base-type=uint8, implementation-data-type=DT_EOL_RMCUActiveReleaseCmd, update-indication-bit-position=-1, to MVCU
          signal EOL_VehicleDirect: start 44, 1 bit, little-endian, init-value=0, base-type=uint8, implementation-data-type=DT_EOL_VehicleDirect, update-indication-bit-position=-1, to MVCU
          signal EOL_SuppressJitterRMCURequest: start 46, 1 bit, little-endian, init-value=0, base-type=uint8, implementation-data-type=DT_EOL_SuppressJitterRMCURequest, update-indication-bit-position=-1, to MVCU
          signal EOL_RDrvControlMode: start 47, 1 bit, little-endian, init-value=0, base-type=uint8, implementation-data-type=DT_EOL_RDrvControlMode, update-indication-bit-position=-1, to MVCU
          signal EOL_BrakePedalValue: start 48, 8 bit, little-endian, init-value=0, base-type=uint8, implementation-data-type=DT_EOL_BrakePedalValue, update-indication-bit-position=-1, to MVCU
          signal EOL_RMCUMaxDischargePower: start 56, 9 bit, little-endian, init-value=0, base-type=uint16, implementation-data-type=DT_EOL_RMCUMaxDischargePower, update-indication-bit-position=-1, to MVCU
          signal EOL_RMCUMaxChargePower: start 71, 9 bit, little-endian, init-value=0, base-type=uint16, implementation-data-type=DT_EOL_RMCUMaxChargePower, update-indication-bit-position=-1, to MVCU
          signal EOL_RDrvRequestTorque: start 80, 16 bit, little-endian, init-value=0, base-type=uint16, implementation-data-type=DT_EOL_RDrvRequestTorque, update-indication-bit-position=-1, to MVCU
          signal EOL_RDrvRequesSpeed: start 96, 16 bit, little-endian, init-value=0, base-type=uint16, implementation-data-type=DT_EOL_RDrvRequesSpeed, update-indication-bit-position=-1, to MVCU
          signal EOL_FDrvRequestTorque: start 112, 16 bit, little-endian, init-value=0, base-type=uint16, implementation-data-type=DT_EOL_FDrvRequestTorque, update-indication-bit-position=-1, to MVCU
          signal EOL_FDrvRequesSpeed: start 128, 16 bit, little-endian, init-value=0, base-type=uint16, implementation-data-type=DT_EOL_FDrvRequesSpeed, update-indication-bit-position=-1, to MVCU
          signal EOL_FVehicleSts: start 144, 1 bit, little-endian, init-value=0, base-type=uint8, implementation-data-type=DT_EOL_FVehicleSts, update-indication-bit-position=-1, to MVCU
          signal EOL_FDrvControlMode: start 148, 1 bit, little-endian, init-value=0, base-type=uint8, implementation-data-type=DT_EOL_FDrvControlMode, update-indication-bit-position=-1, to MVCU
          signal EOL_ON2BRelayReq: start 149, 2 bit, little-endian, init-value=0, base-type=uint8, implementation-data-type=DT_EOL_ON2BRelayReq, update-indication-bit-position=-1, to MVCU
          signal EOL_VehicleDirectVD: start 177, 1 bit, little-endian, init-value=0, base-type=uint8, implementation-data-type=DT_EOL_VehicleDirectVD, update-indication-bit-position=-1, to MVCU
          signal EOL_RDrvControlModeVD: start 178, 1 bit, little-endian, init-value=0, base-type=uint8, implementation-data-type=DT_EOL_RDrvControlModeVD, update-indication-bit-position=-1, to MVCU
          signal EOL_RDrvRequestTorqueVD: start 179, 1 bit, little-endian, init-value=0, base-type=uint8, implementation-data-type=DT_EOL_RDrvRequestTorqueVD, update-indication-bit-position=-1, to MVCU
          signal EOL_RDrvRequesSpeedVD: start 180, 1 bit, little-endian, init-value=0, base-type=uint8, implementation-data-type=DT_EOL_RDrvRequesSpeedVD, update-indication-bit-position=-1, to MVCU
          signal EOL_FDrvRequestTorqueVD: start 181, 1 bit, little-endian, init-value=0, base-type=uint8, implementation-data-type=DT_EOL_FDrvRequestTorqueVD, update-indication-bit-position=-1, to MVCU
          signal EOL_FDrvRequesSpeedVD: start 182, 1 bit, little-endian, init-value=0, base-type=uint8, implementation-data-type=DT_EOL_FDrvRequesSpeedVD, update-indication-bit-position=-1, to MVCU
          signal EOL_FDrvControlModeVD: start 183, 1 bit, little-endian, init-value=0, base-type=uint8, implementation-data-type=DT_EOL_FDrvControlModeVD, update-indication-bit-position=-1, to MVCU
          signal EOL_MCUMDampgLmtFactor: start 202, 7 bit, little-endian, init-value=0, base-type=uint8, implementation-data-type=DT_EOL_MCUMDampgLmtFactor, update-indication-bit-position=-1, to MVCU
          signal EOL_MCUMMaxPosDampgTrq: start 244, 6 bit, little-endian, init-value=0, base-type=uint8, implementation-data-type=DT_EOL_MCUMMaxPosDampgTrq, update-indication-bit-position=-1, to MVCU
          signal EOL_MCUMMaxNegDampgTrq: start 250, 6 bit, little-endian, init-value=0, base-type=uint8, implementation-data-type=DT_EOL_MCUMMaxNegDampgTrq, update-indication-bit-position=-1, to MVCU
          signal EOL_VCU_BoostMode_Fail: start 221, 3 bit, little-endian, init-value=0, base-type=uint8, update-indication-bit-position=-1, to MVCU
          signal EOL_VCU_BoostModeSts: start 224, 2 bit, little-endian, init-value=0, base-type=uint8, update-indication-bit-position=-1, to MVCU
      frame OBD_Phy_Rx_7E3_MCUM: id 0x7E3, to MVCU, frame-length=8, can-addressing-mode=STANDARD, can-fd-frame-support=true
        carries pdu OBD_Phy_Rx_7E3_MCUM: packing-byte-order=big-endian, start-position=7, update-indication-bit-position=-1
        dcm i pdu OBD_Phy_Rx_7E3_MCUM: length=8, diag-pdu-type=DIAG-REQUEST
      frame GCU_0xBD: id 0xBD, to MVCU, frame-length=32, can-addressing-mode=STANDARD, can-fd-frame-support=true, can-frame-rx-behavior=CAN-FD
        carries pdu GCU_0xBD: packing-byte-order=little-endian, start-position=0, update-indication-bit-position=-1
        pdu GCU_0xBD: length=32, transmission-mode-false-timing=cyclic-timing={time-offset=0.0, time-period=0.01}, transmission-mode-true-timing=cyclic-timing={time-offset=0.0, time-period=0.01}
          transmission-mode-conditions:
            {data-filter={data-filter-type=ALWAYS, max=255, min=0, offset=0}, i-signal-in-i-pdu=GCU_CRC_BD}
            {data-filter={data-filter-type=ALWAYS, max=3, min=0, offset=0}, i-signal-in-i-pdu=GCU_EngineCylinderDeactivationStatus}
            {data-filter={data-filter-type=ALWAYS, max=1, min=0, offset=0}, i-signal-in-i-pdu=GCU_EngineFuelInhibitReq}
            {data-filter={data-filter-type=ALWAYS, max=15, min=0, offset=0}, i-signal-in-i-pdu=GCU_RollingCounter_BD}
            {data-filter={data-filter-type=NEW-IS-WITHIN, max=20000, min=0}, i-signal-in-i-pdu=GCU_MainWireCurr}
            {data-filter={data-filter-type=NEW-IS-WITHIN, max=5000, min=0, offset=0}, i-signal-in-i-pdu=GCU_MainWireVolt}
            {data-filter={data-filter-type=ALWAYS, max=1, min=0, offset=0}, i-signal-in-i-pdu=GCU_SystemWarning}
            {data-filter={data-filter-type=ALWAYS, max=1, min=0, offset=0}, i-signal-in-i-pdu=GCU_MILlampReq}
            {data-filter={data-filter-type=ALWAYS, max=250, min=0}, i-signal-in-i-pdu=GCU_MoterTemp}
            {data-filter={data-filter-type=ALWAYS, max=250, min=0}, i-signal-in-i-pdu=GCU_Temp}
            {data-filter={data-filter-type=ALWAYS, max=3, min=0, offset=0}, i-signal-in-i-pdu=GCU_SelfCheck}
            {data-filter={data-filter-type=ALWAYS, max=3, min=0, offset=0}, i-signal-in-i-pdu=GCU_Warning_Level}
            {data-filter={data-filter-type=ALWAYS, max=1, min=0, offset=0}, i-signal-in-i-pdu=GCU_HVILSts}
            {data-filter={data-filter-type=ALWAYS, max=1, min=0, offset=0}, i-signal-in-i-pdu=GCU__PowerReduceSts}
            {data-filter={data-filter-type=ALWAYS, max=1, min=0, offset=0}, i-signal-in-i-pdu=GCU_ActualMotorRPM_VD}
            {data-filter={data-filter-type=ALWAYS, max=1, min=0, offset=0}, i-signal-in-i-pdu=GCU_ActualMotorTorque_VD}
            {data-filter={data-filter-type=NEW-IS-WITHIN, max=4000, min=0}, i-signal-in-i-pdu=GCU_ActualMotorTorque}
            {data-filter={data-filter-type=NEW-IS-WITHIN, max=4000, min=0}, i-signal-in-i-pdu=GCU_MaxTorque}
            {data-filter={data-filter-type=ALWAYS, max=3, min=0, offset=0}, i-signal-in-i-pdu=GCU_ActiveReleaseFB}
            {data-filter={data-filter-type=ALWAYS, max=250, min=0, offset=0}, i-signal-in-i-pdu=GCU_MAXPower}
            {data-filter={data-filter-type=NEW-IS-WITHIN, max=2500, min=0, offset=0}, i-signal-in-i-pdu=GCU_TransientPower}
            {data-filter={data-filter-type=ALWAYS, max=1, min=0, offset=0}, i-signal-in-i-pdu=GCU_HVOffReq}
            {data-filter={data-filter-type=ALWAYS, max=7, min=0, offset=0}, i-signal-in-i-pdu=GCU_ControlMode}
            {data-filter={data-filter-type=ALWAYS, max=14, min=0, offset=0}, i-signal-in-i-pdu=GCU_Operating_Mode}
            {data-filter={data-filter-type=NEW-IS-WITHIN, max=47000, min=0}, i-signal-in-i-pdu=GCU_ActualMotorRPM}
          signal GCU_CRC_BD: start 0, 8 bit, little-endian, init-value=0, base-type=uint8, implementation-data-type=DT_GCU_CRC_BD, update-indication-bit-position=-1, to MVCU
          signal GCU_EngineCylinderDeactivationStatus: start 160, 2 bit, little-endian, init-value=0, base-type=uint8, implementation-data-type=DT_GCU_EngineCylinderDeactivationStatus, update-indication-bit-position=-1, to MVCU
          signal GCU_EngineFuelInhibitReq: start 96, 1 bit, little-endian, init-value=0, base-type=uint8, implementation-data-type=DT_GCU_EngineFuelInhibitReq, update-indication-bit-position=-1, to MVCU
          signal GCU_RollingCounter_BD: start 8, 4 bit, little-endian, init-value=0, base-type=uint8, implementation-data-type=DT_GCU_RollingCounter_BD, update-indication-bit-position=-1, to MVCU
          signal GCU_MainWireCurr: start 16, 16 bit, little-endian, init-value=0, base-type=uint16, implementation-data-type=DT_GCU_MainWireCurr, update-indication-bit-position=-1, to MVCU
          signal GCU_MainWireVolt: start 32, 13 bit, little-endian, init-value=0, base-type=uint16, implementation-data-type=DT_GCU_MainWireVolt, update-indication-bit-position=-1, to MVCU
          signal GCU_SystemWarning: start 45, 1 bit, little-endian, init-value=0, base-type=uint8, implementation-data-type=DT_GCU_SystemWarning, update-indication-bit-position=-1, to MVCU
          signal GCU_MILlampReq: start 46, 1 bit, little-endian, init-value=0, base-type=uint8, implementation-data-type=DT_GCU_MILlampReq, update-indication-bit-position=-1, to MVCU
          signal GCU_MoterTemp: start 48, 8 bit, little-endian, init-value=0, base-type=uint8, implementation-data-type=DT_GCU_MoterTemp, update-indication-bit-position=-1, to MVCU
          signal GCU_Temp: start 56, 8 bit, little-endian, init-value=0, base-type=uint8, implementation-data-type=DT_GCU_Temp, update-indication-bit-position=-1, to MVCU
          signal GCU_SelfCheck: start 64, 2 bit, little-endian, init-value=0, base-type=uint8, implementation-data-type=DT_GCU_SelfCheck, update-indication-bit-position=-1, to MVCU
          signal GCU_Warning_Level: start 66, 2 bit, little-endian, init-value=0, base-type=uint8, implementation-data-type=DT_GCU_Warning_Level, update-indication-bit-position=-1, to MVCU
          signal GCU_HVILSts: start 68, 1 bit, little-endian, init-value=0, base-type=uint8, implementation-data-type=DT_GCU_HVILSts, update-indication-bit-position=-1, to MVCU
          signal GCU__PowerReduceSts: start 69, 1 bit, little-endian, init-value=0, base-type=uint8, implementation-data-type=DT_GCU__PowerReduceSts, update-indication-bit-position=-1, to MVCU
          signal GCU_ActualMotorRPM_VD: start 70, 1 bit, little-endian, init-value=0, base-type=uint8, implementation-data-type=DT_GCU_ActualMotorRPM_VD, update-indication-bit-position=-1, to MVCU
          signal GCU_ActualMotorTorque_VD: start 71, 1 bit, little-endian, init-value=0, base-type=uint8, implementation-data-type=DT_GCU_ActualMotorTorque_VD, update-indication-bit-position=-1, to MVCU
          signal GCU_ActualMotorTorque: start 72, 12 bit, little-endian, init-value=0, base-type=uint16, implementation-data-type=DT_GCU_ActualMotorTorque, update-indication-bit-position=-1, to MVCU
          signal GCU_MaxTorque: start 84, 12 bit, little-endian, init-value=0, base-type=uint16, implementation-data-type=DT_GCU_MaxTorque, update-indication-bit-position=-1, to MVCU
          signal GCU_ActiveReleaseFB: start 110, 2 bit, little-endian, init-value=0, base-type=uint8, implementation-data-type=DT_GCU_ActiveReleaseFB, update-indication-bit-position=-1, to MVCU
          signal GCU_MAXPower: start 112, 8 bit, little-endian, init-value=0, base-type=uint8, implementation-data-type=DT_GCU_MAXPower, update-indication-bit-position=-1, to MVCU
          signal GCU_TransientPower: start 120, 12 bit, little-endian, init-value=0, base-type=uint16, implementation-data-type=DT_GCU_TransientPower, update-indication-bit-position=-1, to MVCU
          signal GCU_HVOffReq: start 132, 1 bit, little-endian, init-value=0, base-type=uint8, implementation-data-type=DT_GCU_HVOffReq, update-indication-bit-position=-1, to MVCU
          signal GCU_ControlMode: start 133, 3 bit, little-endian, init-value=0, base-type=uint8, implementation-data-type=DT_GCU_ControlMode, update-indication-bit-position=-1, to MVCU
          signal GCU_Operating_Mode: start 140, 4 bit, little-endian, init-value=0, base-type=uint8, implementation-data-type=DT_GCU_Operating_Mode, update-indication-bit-position=-1, to MVCU
          signal GCU_ActualMotorRPM: start 144, 16 bit, little-endian, init-value=0, base-type=uint16, implementation-data-type=DT_GCU_ActualMotorRPM, update-indication-bit-position=-1, to MVCU
      frame RMCU_0x2: id 0x2, to MVCU, frame-length=32, can-addressing-mode=STANDARD, can-fd-frame-support=true, can-frame-rx-behavior=CAN-FD
        carries pdu RMCU_0x2: packing-byte-order=little-endian, start-position=0, update-indication-bit-position=-1
        pdu RMCU_0x2: length=32, transmission-mode-false-timing=cyclic-timing={time-offset=0.0, time-period=0.01}, transmission-mode-true-timing=cyclic-timing={time-offset=0.0, time-period=0.01}
          transmission-mode-conditions:
            {data-filter={data-filter-type=ALWAYS, max=255, min=0, offset=0}, i-signal-in-i-pdu=Debug_MCU_CRC_CA}
            {data-filter={data-filter-type=ALWAYS, max=15, min=0, offset=0}, i-signal-in-i-pdu=Debug_MCU_RollingCounter_CA}
            {data-filter={data-filter-type=ALWAYS, max=3, min=0, offset=0}, i-signal-in-i-pdu=Debug_MCU_WarningLevel}
            {data-filter={data-filter-type=ALWAYS, max=3, min=0, offset=0}, i-signal-in-i-pdu=Debug_MCU_SelfCheckSts}
            {data-filter={data-filter-type=ALWAYS, max=3, min=0, offset=0}, i-signal-in-i-pdu=Debug_MCU_DrvMotorWorkSts}
            {data-filter={data-filter-type=ALWAYS, max=1, min=0, offset=0}, i-signal-in-i-pdu=Debug_MCU_PowerReduceSts}
            {data-filter={data-filter-type=NEW-IS-WITHIN, max=47000, min=0}, i-signal-in-i-pdu=Debug_MCU_DrvMotorRPM}
            {data-filter={data-filter-type=NEW-IS-WITHIN, max=10000, min=0}, i-signal-in-i-pdu=Debug_MCU_ActualTorqueFB}
            {data-filter={data-filter-type=ALWAYS, max=1, min=0, offset=0}, i-signal-in-i-pdu=Debug_MCU_HWRdcFault}
            {data-filter={data-filter-type=ALWAYS, max=1, min=0, offset=0}, i-signal-in-i-pdu=Debug_MCU_HighVoltPowerOffReq}
            {data-filter={data-filter-type=ALWAYS, max=1, min=0, offset=0}, i-signal-in-i-pdu=Debug_MCU_HVILSts}
            {data-filter={data-filter-type=ALWAYS, max=3, min=0, offset=0}, i-signal-in-i-pdu=Debug_MCU_DragSts}
            {data-filter={data-filter-type=ALWAYS, max=1, min=0, offset=0}, i-signal-in-i-pdu=Debug_MCU_CtrlMode}
            {data-filter={data-filter-type=ALWAYS, max=1, min=0, offset=0}, i-signal-in-i-pdu=Debug_MCU_MILlampReq}
            {data-filter={data-filter-type=ALWAYS, max=1, min=0, offset=0}, i-signal-in-i-pdu=Debug_MCU_DrvMotorRPMVD}
            {data-filter={data-filter-type=ALWAYS, max=1, min=0, offset=0}, i-signal-in-i-pdu=Debug_MCU_ActualTorqueFBVD}
            {data-filter={data-filter-type=NEW-IS-WITHIN, max=10000, min=0}, i-signal-in-i-pdu=Debug_MCU_MaxTorqueAllow}
            {data-filter={data-filter-type=NEW-IS-WITHIN, max=34000, min=0}, i-signal-in-i-pdu=Debug_MCU_MaxSpeedAllow}
            {data-filter={data-filter-type=ALWAYS, max=3, min=0, offset=0}, i-signal-in-i-pdu=Debug_MCU_ActiveReleaseSts}
            {data-filter={data-filter-type=ALWAYS, max=1, min=0, offset=0}, i-signal-in-i-pdu=Debug_MCU_DCChargRelaySts}
            {data-filter={data-filter-type=NEW-IS-WITHIN, max=10000, min=0}, i-signal-in-i-pdu=Debug_MCUM_MinTorqueAllow}
            {data-filter={data-filter-type=NEW-IS-WITHIN, max=10000, min=0, offset=0}, i-signal-in-i-pdu=Debug_MCU_MainWireVolt}
            {data-filter={data-filter-type=NEW-IS-WITHIN, max=20000, min=0}, i-signal-in-i-pdu=Debug_MCU_MainWireCurr}
            {data-filter={data-filter-type=ALWAYS, max=1, min=0, offset=0}, i-signal-in-i-pdu=Debug_MCUM_TMS_MotSelfHeatEnSts}
            {data-filter={data-filter-type=ALWAYS, max=7, min=0, offset=0}, i-signal-in-i-pdu=Debug_MCUM_TMS_MotSelfHeatLvlFb}
            {data-filter={data-filter-type=ALWAYS, max=1, min=0, offset=0}, i-signal-in-i-pdu=Debug_MCUM_RPowerReduceSts}
            {data-filter={data-filter-type=ALWAYS, max=31, min=0, offset=0}, i-signal-in-i-pdu=Debug_MCUM_HeatPwrAval}
            {data-filter={data-filter-type=ALWAYS, max=1, min=0, offset=0}, i-signal-in-i-pdu=Debug_MCUM_RCtrlMode}
            {data-filter={data-filter-type=ALWAYS, max=3, min=0, offset=0}, i-signal-in-i-pdu=Debug_MCUM_RWarningLevel}
            {data-filter={data-filter-type=ALWAYS, max=3, min=0, offset=0}, i-signal-in-i-pdu=Debug_MCUM_RSelfCheckSts}
            {data-filter={data-filter-type=ALWAYS, max=3, min=0, offset=0}, i-signal-in-i-pdu=Debug_MCUM_RDrvMotorWorkSts}
            {data-filter={data-filter-type=ALWAYS, max=1, min=0, offset=0}, i-signal-in-i-pdu=Debug_MCUM_RCtrlModeVD}
            {data-filter={data-filter-type=ALWAYS, max=1, min=0, offset=0}, i-signal-in-i-pdu=Debug_MCUM_RHWRdcFault}
            {data-filter={data-filter-type=ALWAYS, max=1, min=0, offset=0}, i-signal-in-i-pdu=Debug_MCUM_RDrvMotorRPMVD}
            {data-filter={data-filter-type=ALWAYS, max=1, min=0, offset=0}, i-signal-in-i-pdu=Debug_MCUM_RActualTorqueFBVD}
            {data-filter={data-filter-type=ALWAYS, max=65535, min=0, offset=0}, i-signal-in-i-pdu=Debug_MCUM_RDrvMotorRPM}
            {data-filter={data-filter-type=ALWAYS, max=65535, min=0, offset=0}, i-signal-in-i-pdu=Debug_MCUM_RActualTorqueFB}
          signal Debug_MCU_CRC_CA: start 0, 8 bit, little-endian, init-value=0, base-type=uint8, implementation-data-type=DT_Debug_MCU_CRC_CA, update-indication-bit-position=-1, to MVCU
          signal Debug_MCU_RollingCounter_CA: start 8, 4 bit, little-endian, init-value=0, base-type=uint8, implementation-data-type=DT_Debug_MCU_RollingCounter_CA, update-indication-bit-position=-1, to MVCU
          signal Debug_MCU_WarningLevel: start 16, 2 bit, little-endian, init-value=0, base-type=uint8, implementation-data-type=DT_Debug_MCU_WarningLevel, update-indication-bit-position=-1, to MVCU
          signal Debug_MCU_SelfCheckSts: start 18, 2 bit, little-endian, init-value=0, base-type=uint8, implementation-data-type=DT_Debug_MCU_SelfCheckSts, update-indication-bit-position=-1, to MVCU
          signal Debug_MCU_DrvMotorWorkSts: start 20, 2 bit, little-endian, init-value=0, base-type=uint8, implementation-data-type=DT_Debug_MCU_DrvMotorWorkSts, update-indication-bit-position=-1, to MVCU
          signal Debug_MCU_PowerReduceSts: start 22, 1 bit, little-endian, init-value=0, base-type=uint8, implementation-data-type=DT_Debug_MCU_PowerReduceSts, update-indication-bit-position=-1, to MVCU
          signal Debug_MCU_DrvMotorRPM: start 24, 16 bit, little-endian, init-value=0, base-type=uint16, implementation-data-type=DT_Debug_MCU_DrvMotorRPM, update-indication-bit-position=-1, to MVCU
          signal Debug_MCU_ActualTorqueFB: start 40, 16 bit, little-endian, init-value=0, base-type=uint16, implementation-data-type=DT_Debug_MCU_ActualTorqueFB, update-indication-bit-position=-1, to MVCU
          signal Debug_MCU_HWRdcFault: start 56, 1 bit, little-endian, init-value=0, base-type=uint8, implementation-data-type=DT_Debug_MCU_HWRdcFault, update-indication-bit-position=-1, to MVCU
          signal Debug_MCU_HighVoltPowerOffReq: start 58, 1 bit, little-endian, init-value=0, base-type=uint8, implementation-data-type=DT_Debug_MCU_HighVoltPowerOffReq, update-indication-bit-position=-1, to MVCU
          signal Debug_MCU_HVILSts: start 59, 1 bit, little-endian, init-value=0, base-type=uint8, implementation-data-type=DT_Debug_MCU_HVILSts, update-indication-bit-position=-1, to MVCU
          signal Debug_MCU_DragSts: start 60, 2 bit, little-endian, init-value=0, base-type=uint8, implementation-data-type=DT_Debug_MCU_DragSts, update-indication-bit-position=-1, to MVCU
          signal Debug_MCU_CtrlMode: start 62, 1 bit, little-endian, init-value=0, base-type=uint8, implementation-data-type=DT_Debug_MCU_CtrlMode, update-indication-bit-position=-1, to MVCU
          signal Debug_MCU_MILlampReq: start 65, 1 bit, little-endian, init-value=0, base-type=uint8, implementation-data-type=DT_Debug_MCU_MILlampReq, update-indication-bit-position=-1, to MVCU
          signal Debug_MCU_DrvMotorRPMVD: start 68, 1 bit, little-endian, init-value=0, base-type=uint8, implementation-data-type=DT_Debug_MCU_DrvMotorRPMVD, update-indication-bit-position=-1, to MVCU
          signal Debug_MCU_ActualTorqueFBVD: start 69, 1 bit, little-endian, init-value=0, base-type=uint8, implementation-data-type=DT_Debug_MCU_ActualTorqueFBVD, update-indication-bit-position=-1, to MVCU
          signal Debug_MCU_MaxTorqueAllow: start 72, 16 bit, little-endian, init-value=0, base-type=uint16, implementation-data-type=DT_Debug_MCU_MaxTorqueAllow, update-indication-bit-position=-1, to MVCU
          signal Debug_MCU_MaxSpeedAllow: start 88, 16 bit, little-endian, init-value=0, base-type=uint16, implementation-data-type=DT_Debug_MCU_MaxSpeedAllow, update-indication-bit-position=-1, to MVCU
          signal Debug_MCU_ActiveReleaseSts: start 108, 2 bit, little-endian, init-value=0, base-type=uint8, implementation-data-type=DT_Debug_MCU_ActiveReleaseSts, update-indication-bit-position=-1, to MVCU
          signal Debug_MCU_DCChargRelaySts: start 110, 1 bit, little-endian, init-value=0, base-type=uint8, implementation-data-type=DT_Debug_MCU_DCChargRelaySts, update-indication-bit-position=-1, to MVCU
          signal Debug_MCUM_MinTorqueAllow: start 112, 16 bit, little-endian, init-value=0, base-type=uint16, implementation-data-type=DT_Debug_MCUM_MinTorqueAllow, update-indication-bit-position=-1, to MVCU
          signal Debug_MCU_MainWireVolt: start 128, 16 bit, little-endian, init-value=0, base-type=uint16, implementation-data-type=DT_Debug_MCU_MainWireVolt, update-indication-bit-position=-1, to MVCU
          signal Debug_MCU_MainWireCurr: start 168, 16 bit, little-endian, init-value=0, base-type=uint16, implementation-data-type=DT_Debug_MCU_MainWireCurr, update-indication-bit-position=-1, to MVCU
          signal Debug_MCUM_TMS_MotSelfHeatEnSts: start 184, 1 bit, little-endian, init-value=0, base-type=uint8, implementation-data-type=DT_Debug_MCUM_TMS_MotSelfHeatEnSts, update-indication-bit-position=-1, to MVCU
          signal Debug_MCUM_TMS_MotSelfHeatLvlFb: start 185, 3 bit, little-endian, init-value=0, base-type=uint8, implementation-data-type=DT_Debug_MCUM_TMS_MotSelfHeatLvlFb, update-indication-bit-position=-1, to MVCU
          signal Debug_MCUM_RPowerReduceSts: start 191, 1 bit, little-endian, init-value=0, base-type=uint8, implementation-data-type=DT_Debug_MCUM_RPowerReduceSts, update-indication-bit-position=-1, to MVCU
          signal Debug_MCUM_HeatPwrAval: start 208, 5 bit, little-endian, init-value=0, base-type=uint8, implementation-data-type=DT_Debug_MCUM_HeatPwrAval, update-indication-bit-position=-1, to MVCU
          signal Debug_MCUM_RCtrlMode: start 213, 1 bit, little-endian, init-value=0, base-type=uint8, implementation-data-type=DT_Debug_MCUM_RCtrlMode, update-indication-bit-position=-1
          signal Debug_MCUM_RWarningLevel: start 214, 2 bit, little-endian, init-value=0, base-type=uint8, implementation-data-type=DT_Debug_MCUM_RWarningLevel, update-indication-bit-position=-1
          signal Debug_MCUM_RSelfCheckSts: start 216, 2 bit, little-endian, init-value=0, base-type=uint8, implementation-data-type=DT_Debug_MCUM_RSelfCheckSts, update-indication-bit-position=-1
          signal Debug_MCUM_RDrvMotorWorkSts: start 218, 2 bit, little-endian, init-value=0, base-type=uint8, implementation-data-type=DT_Debug_MCUM_RDrvMotorWorkSts, update-indication-bit-position=-1
          signal Debug_MCUM_RCtrlModeVD: start 220, 1 bit, little-endian, init-value=0, base-type=uint8, implementation-data-type=DT_Debug_MCUM_RCtrlModeVD, update-indication-bit-position=-1
          signal Debug_MCUM_RHWRdcFault: start 221, 1 bit, little-endian, init-value=0, base-type=uint8, implementation-data-type=DT_Debug_MCUM_RHWRdcFault, update-indication-bit-position=-1
          signal Debug_MCUM_RDrvMotorRPMVD: start 222, 1 bit, little-endian, init-value=0, base-type=uint8, implementation-data-type=DT_Debug_MCUM_RDrvMotorRPMVD, update-indication-bit-position=-1
          signal Debug_MCUM_RActualTorqueFBVD: start 223, 1 bit, little-endian, init-value=0, base-type=uint8, implementation-data-type=DT_Debug_MCUM_RActualTorqueFBVD, update-indication-bit-position=-1
          signal Debug_MCUM_RDrvMotorRPM: start 224, 16 bit, little-endian, init-value=0, base-type=uint16, implementation-data-type=DT_Debug_MCUM_RDrvMotorRPM, update-indication-bit-position=-1
          signal Debug_MCUM_RActualTorqueFB: start 240, 16 bit, little-endian, init-value=0, base-type=uint16, implementation-data-type=DT_Debug_MCUM_RActualTorqueFB, update-indication-bit-position=-1
      frame ICU_0x249: id 0x249, to MVCU, frame-length=64, can-addressing-mode=STANDARD, can-fd-frame-support=true, can-frame-rx-behavior=CAN-FD
        carries pdu ICU_0x249: packing-byte-order=little-endian, start-position=0, update-indication-bit-position=-1
        pdu ICU_0x249: length=64, transmission-mode-false-timing=cyclic-timing={time-offset=0.0, time-period=0.1}, transmission-mode-true-timing=cyclic-timing={time-offset=0.0, time-period=0.1}
          transmission-mode-conditions:
            {data-filter={data-filter-type=NEW-IS-WITHIN, max=999999, min=0, offset=0}, i-signal-in-i-pdu=ICU_TotalOilmeterkm}
            {data-filter={data-filter-type=NEW-IS-WITHIN, max=2000, min=0, offset=0}, i-signal-in-i-pdu=ICU_CLTCoilMileage}
            {data-filter={data-filter-type=NEW-IS-WITHIN, max=2000, min=0, offset=0}, i-signal-in-i-pdu=ICU_WLTC_oilMileage}
            {data-filter={data-filter-type=NEW-IS-WITHIN, max=2000, min=0, offset=0}, i-signal-in-i-pdu=ICU_CLTC_ElectticityMileage}
            {data-filter={data-filter-type=NEW-IS-WITHIN, max=2000, min=0, offset=0}, i-signal-in-i-pdu=ICU_WLTC_ElectticityMileage}
            {data-filter={data-filter-type=ALWAYS, max=7, min=0, offset=0}, i-signal-in-i-pdu=ICU_Switch_CLTCOrWLTC}
            {data-filter={data-filter-type=NEW-IS-WITHIN, max=1000, min=0, offset=0}, i-signal-in-i-pdu=ICU_FuelPercent}
          signal ICU_TotalOilmeterkm: start 44, 20 bit, little-endian, init-value=0, base-type=uint32, implementation-data-type=DT_ICU_TotalOilmeterkm, update-indication-bit-position=-1, to MVCU
          signal ICU_CLTCoilMileage: start 64, 11 bit, little-endian, init-value=0, base-type=uint16, implementation-data-type=DT_ICU_CLTCoilMileage, update-indication-bit-position=-1, to MVCU
          signal ICU_WLTC_oilMileage: start 75, 11 bit, little-endian, init-value=0, base-type=uint16, implementation-data-type=DT_ICU_WLTC_oilMileage, update-indication-bit-position=-1, to MVCU
          signal ICU_CLTC_ElectticityMileage: start 86, 11 bit, little-endian, init-value=0, base-type=uint16, implementation-data-type=DT_ICU_CLTC_ElectticityMileage, update-indication-bit-position=-1, to MVCU
          signal ICU_WLTC_ElectticityMileage: start 97, 11 bit, little-endian, init-value=0, base-type=uint16, implementation-data-type=DT_ICU_WLTC_ElectticityMileage, update-indication-bit-position=-1, to MVCU
          signal ICU_Switch_CLTCOrWLTC: start 128, 3 bit, little-endian, init-value=0, base-type=uint8, implementation-data-type=DT_ICU_Switch_CLTCOrWLTC, update-indication-bit-position=-1, to MVCU
          signal ICU_FuelPercent: start 135, 10 bit, little-endian, init-value=0, base-type=uint16, implementation-data-type=DT_ICU_FuelPercent, update-indication-bit-position=-1, to MVCU
      frame HPCBCM_0x1E6: id 0x1E6, to MVCU, frame-length=16, can-addressing-mode=STANDARD, can-fd-frame-support=true, can-frame-rx-behavior=CAN-FD
        carries pdu HPCBCM_0x1E6: packing-byte-order=little-endian, start-position=0, update-indication-bit-position=-1
        pdu HPCBCM_0x1E6: length=16
          transmission-mode-conditions:
            {data-filter={data-filter-type=ALWAYS, max=255, min=0, offset=0}, i-signal-in-i-pdu=BCM_VCU_Authentication_MAC_B{0..15}}
          signal BCM_VCU_Authentication_MAC_B0: start 0, 8 bit, little-endian, init-value=0, base-type=uint8, implementation-data-type=DT_BCM_VCU_Authentication_MAC_B0, update-indication-bit-position=-1, to MVCU
          signal BCM_VCU_Authentication_MAC_B1: start 8, 8 bit, little-endian, init-value=0, base-type=uint8, implementation-data-type=DT_BCM_VCU_Authentication_MAC_B1, update-indication-bit-position=-1, to MVCU
          signal BCM_VCU_Authentication_MAC_B2: start 16, 8 bit, little-endian, init-value=0, base-type=uint8, implementation-data-type=DT_BCM_VCU_Authentication_MAC_B2, update-indication-bit-position=-1, to MVCU
          signal BCM_VCU_Authentication_MAC_B3: start 24, 8 bit, little-endian, init-value=0, base-type=uint8, implementation-data-type=DT_BCM_VCU_Authentication_MAC_B3, update-indication-bit-position=-1, to MVCU
          signal BCM_VCU_Authentication_MAC_B4: start 32, 8 bit, little-endian, init-value=0, base-type=uint8, implementation-data-type=DT_BCM_VCU_Authentication_MAC_B4, update-indication-bit-position=-1, to MVCU
          signal BCM_VCU_Authentication_MAC_B5: start 40, 8 bit, little-endian, init-value=0, base-type=uint8, implementation-data-type=DT_BCM_VCU_Authentication_MAC_B5, update-indication-bit-position=-1, to MVCU
          signal BCM_VCU_Authentication_MAC_B6: start 48, 8 bit, little-endian, init-value=0, base-type=uint8, implementation-data-type=DT_BCM_VCU_Authentication_MAC_B6, update-indication-bit-position=-1, to MVCU
          signal BCM_VCU_Authentication_MAC_B7: start 56, 8 bit, little-endian, init-value=0, base-type=uint8, implementation-data-type=DT_BCM_VCU_Authentication_MAC_B7, update-indication-bit-position=-1, to MVCU
          signal BCM_VCU_Authentication_MAC_B8: start 64, 8 bit, little-endian, init-value=0, base-type=uint8, implementation-data-type=DT_BCM_VCU_Authentication_MAC_B8, update-indication-bit-position=-1, to MVCU
          signal BCM_VCU_Authentication_MAC_B9: start 72, 8 bit, little-endian, init-value=0, base-type=uint8, implementation-data-type=DT_BCM_VCU_Authentication_MAC_B9, update-indication-bit-position=-1, to MVCU
          signal BCM_VCU_Authentication_MAC_B10: start 80, 8 bit, little-endian, init-value=0, base-type=uint8, implementation-data-type=DT_BCM_VCU_Authentication_MAC_B10, update-indication-bit-position=-1, to MVCU
          signal BCM_VCU_Authentication_MAC_B11: start 88, 8 bit, little-endian, init-value=0, base-type=uint8, implementation-data-type=DT_BCM_VCU_Authentication_MAC_B11, update-indication-bit-position=-1, to MVCU
          signal BCM_VCU_Authentication_MAC_B12: start 96, 8 bit, little-endian, init-value=0, base-type=uint8, implementation-data-type=DT_BCM_VCU_Authentication_MAC_B12, update-indication-bit-position=-1, to MVCU
          signal BCM_VCU_Authentication_MAC_B13: start 104, 8 bit, little-endian, init-value=0, base-type=uint8, implementation-data-type=DT_BCM_VCU_Authentication_MAC_B13, update-indication-bit-position=-1, to MVCU
          signal BCM_VCU_Authentication_MAC_B14: start 112, 8 bit, little-endian, init-value=0, base-type=uint8, implementation-data-type=DT_BCM_VCU_Authentication_MAC_B14, update-indication-bit-position=-1, to MVCU
          signal BCM_VCU_Authentication_MAC_B15: start 120, 8 bit, little-endian, init-value=0, base-type=uint8, implementation-data-type=DT_BCM_VCU_Authentication_MAC_B15, update-indication-bit-position=-1, to MVCU
      frame BMS_0x310: id 0x310, to MVCU, frame-length=32, can-addressing-mode=STANDARD, can-fd-frame-support=true, can-frame-rx-behavior=CAN-FD
        carries pdu BMS_0x310: packing-byte-order=little-endian, start-position=0, update-indication-bit-position=-1
        pdu BMS_0x310: length=32, transmission-mode-false-timing=cyclic-timing={time-offset=0.0, time-period=0.2}, transmission-mode-true-timing=cyclic-timing={time-offset=0.0, time-period=0.2}
          transmission-mode-conditions:
            {data-filter={data-filter-type=ALWAYS, max=250, min=0, offset=0}, i-signal-in-i-pdu=BMS_InverterPower}
            {data-filter={data-filter-type=NEW-IS-WITHIN, max=10000, min=0, offset=0}, i-signal-in-i-pdu=BMS_MaxChargeVolt}
            {data-filter={data-filter-type=NEW-IS-WITHIN, max=4000, min=0, offset=0}, i-signal-in-i-pdu=BMS_MaxChargeCurr}
            {data-filter={data-filter-type=ALWAYS, max=7, min=0, offset=0}, i-signal-in-i-pdu=BMS_OBCWorkModeCtrl}
            {data-filter={data-filter-type=NEW-IS-WITHIN, max=500, min=0, offset=0}, i-signal-in-i-pdu=BMS_MaxPower}
            {data-filter={data-filter-type=ALWAYS, max=1, min=0, offset=0}, i-signal-in-i-pdu=BMS_ChargerACInput}
            {data-filter={data-filter-type=ALWAYS, max=1, min=0, offset=0}, i-signal-in-i-pdu=BMS_ChargerDCInput}
            {data-filter={data-filter-type=ALWAYS, max=1, min=0, offset=0}, i-signal-in-i-pdu=BMS_ChargeRequest}
            {data-filter={data-filter-type=ALWAYS, max=1, min=0, offset=0}, i-signal-in-i-pdu=BMS_InverterRequest}
            {data-filter={data-filter-type=NEW-IS-WITHIN, max=1000, min=0, offset=0}, i-signal-in-i-pdu=BMS_ChargeQuantity}
            {data-filter={data-filter-type=ALWAYS, max=250, min=0}, i-signal-in-i-pdu=BMS_BattMaxTemp}
            {data-filter={data-filter-type=ALWAYS, max=250, min=0}, i-signal-in-i-pdu=BMS_BattMinTemp}
            {data-filter={data-filter-type=ALWAYS, max=250, min=0}, i-signal-in-i-pdu=BMS_BattIntakeTemp}
            {data-filter={data-filter-type=ALWAYS, max=250, min=0}, i-signal-in-i-pdu=BMS_BattIOutletTemp}
            {data-filter={data-filter-type=NEW-IS-WITHIN, max=1000, min=0, offset=0}, i-signal-in-i-pdu=BMS_BattSOC_Display}
            {data-filter={data-filter-type=ALWAYS, max=1, min=0, offset=0}, i-signal-in-i-pdu=BMS_Req_Cab220VInverter_Sts}
            {data-filter={data-filter-type=ALWAYS, max=1, min=0, offset=0}, i-signal-in-i-pdu=BMS_Req_Cabin220VInverter_Sts}
            {data-filter={data-filter-type=NEW-IS-WITHIN, max=65530, min=0, offset=0}, i-signal-in-i-pdu=BMS_RemainEnergy}
            {data-filter={data-filter-type=NEW-IS-WITHIN, max=65530, min=0, offset=0}, i-signal-in-i-pdu=BMS_StateOfEngeryMax}
            {data-filter={data-filter-type=ALWAYS, max=7, min=0, offset=0}, i-signal-in-i-pdu=BMS_ThermalManageRequest}
            {data-filter={data-filter-type=ALWAYS, max=3, min=0, offset=0}, i-signal-in-i-pdu=BMS_PreHeatingState}
          signal BMS_InverterPower: start 8, 8 bit, little-endian, init-value=0, base-type=uint8, implementation-data-type=DT_BMS_InverterPower, update-indication-bit-position=-1, to MVCU
          signal BMS_MaxChargeVolt: start 16, 16 bit, little-endian, init-value=0, base-type=uint16, implementation-data-type=DT_BMS_MaxChargeVolt, update-indication-bit-position=-1, to MVCU
          signal BMS_MaxChargeCurr: start 32, 12 bit, little-endian, init-value=0, base-type=uint16, implementation-data-type=DT_BMS_MaxChargeCurr, update-indication-bit-position=-1, to MVCU
          signal BMS_OBCWorkModeCtrl: start 44, 3 bit, little-endian, init-value=0, base-type=uint8, implementation-data-type=DT_BMS_OBCWorkModeCtrl, update-indication-bit-position=-1, to MVCU
          signal BMS_MaxPower: start 47, 9 bit, little-endian, init-value=0, base-type=uint16, implementation-data-type=DT_BMS_MaxPower, update-indication-bit-position=-1, to MVCU
          signal BMS_ChargerACInput: start 56, 1 bit, little-endian, init-value=0, base-type=uint8, implementation-data-type=DT_BMS_ChargerACInput, update-indication-bit-position=-1, to MVCU
          signal BMS_ChargerDCInput: start 57, 1 bit, little-endian, init-value=0, base-type=uint8, implementation-data-type=DT_BMS_ChargerDCInput, update-indication-bit-position=-1, to MVCU
          signal BMS_ChargeRequest: start 58, 1 bit, little-endian, init-value=0, base-type=uint8, implementation-data-type=DT_BMS_ChargeRequest, update-indication-bit-position=-1, to MVCU
          signal BMS_InverterRequest: start 59, 1 bit, little-endian, init-value=0, base-type=uint8, implementation-data-type=DT_BMS_InverterRequest, update-indication-bit-position=-1, to MVCU
          signal BMS_ChargeQuantity: start 70, 10 bit, little-endian, init-value=0, base-type=uint16, implementation-data-type=DT_BMS_ChargeQuantity, update-indication-bit-position=-1, to MVCU
          signal BMS_BattMaxTemp: start 80, 8 bit, little-endian, init-value=0, base-type=uint8, implementation-data-type=DT_BMS_BattMaxTemp, update-indication-bit-position=-1, to MVCU
          signal BMS_BattMinTemp: start 88, 8 bit, little-endian, init-value=0, base-type=uint8, implementation-data-type=DT_BMS_BattMinTemp, update-indication-bit-position=-1, to MVCU
          signal BMS_BattIntakeTemp: start 120, 8 bit, little-endian, init-value=0, base-type=uint8, implementation-data-type=DT_BMS_BattIntakeTemp, update-indication-bit-position=-1, to MVCU
          signal BMS_BattIOutletTemp: start 128, 8 bit, little-endian, init-value=0, base-type=uint8, implementation-data-type=DT_BMS_BattIOutletTemp, update-indication-bit-position=-1, to MVCU
          signal BMS_BattSOC_Display: start 144, 10 bit, little-endian, init-value=0, base-type=uint16, implementation-data-type=DT_BMS_BattSOC_Display, update-indication-bit-position=-1, to MVCU
          signal BMS_Req_Cab220VInverter_Sts: start 174, 1 bit, little-endian, init-value=0, base-type=uint8, implementation-data-type=DT_BMS_Req_Cab220VInverter_Sts, update-indication-bit-position=-1, to MVCU
          signal BMS_Req_Cabin220VInverter_Sts: start 175, 1 bit, little-endian, init-value=0, base-type=uint8, implementation-data-type=DT_BMS_Req_Cabin220VInverter_Sts, update-indication-bit-position=-1, to MVCU
          signal BMS_RemainEnergy: start 176, 16 bit, little-endian, init-value=0, base-type=uint16, implementation-data-type=DT_BMS_RemainEnergy, update-indication-bit-position=-1, to MVCU
          signal BMS_StateOfEngeryMax: start 192, 16 bit, little-endian, init-value=0, base-type=uint16, implementation-data-type=DT_BMS_StateOfEngeryMax, update-indication-bit-position=-1, to MVCU
          signal BMS_ThermalManageRequest: start 240, 3 bit, little-endian, init-value=0, base-type=uint8, implementation-data-type=DT_BMS_ThermalManageRequest, update-indication-bit-position=-1, to MVCU
          signal BMS_PreHeatingState: start 244, 2 bit, little-endian, init-value=0, base-type=uint8, implementation-data-type=DT_BMS_PreHeatingState, update-indication-bit-position=-1, to MVCU
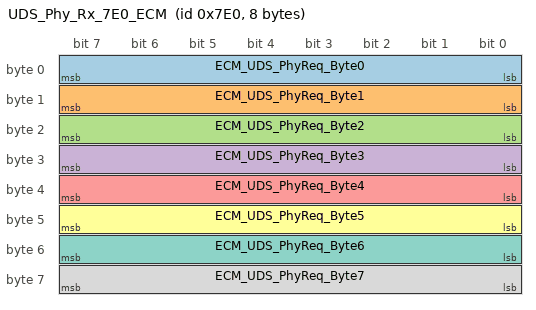
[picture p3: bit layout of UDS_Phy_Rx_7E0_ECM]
      frame UDS_Phy_Rx_7E0_ECM: id 0x7E0, to MVCU, frame-length=8, can-addressing-mode=STANDARD, can-fd-frame-support=true, can-frame-rx-behavior=CAN-20
        carries pdu UDS_Phy_Rx_7E0_ECM: packing-byte-order=little-endian, start-position=0, update-indication-bit-position=-1
        pdu UDS_Phy_Rx_7E0_ECM: length=8
          transmission-mode-conditions:
            {data-filter={data-filter-type=ALWAYS, max=1, min=0, offset=0}, i-signal-in-i-pdu=ECM_UDS_PhyReq_Byte{0..7}}
          signal ECM_UDS_PhyReq_Byte0: start 0, 8 bit, little-endian, init-value=0, base-type=uint8, implementation-data-type=DT_ECM_UDS_PhyReq_Byte0, update-indication-bit-position=-1, to MVCU
          signal ECM_UDS_PhyReq_Byte1: start 8, 8 bit, little-endian, init-value=0, base-type=uint8, implementation-data-type=DT_ECM_UDS_PhyReq_Byte1, update-indication-bit-position=-1, to MVCU
          signal ECM_UDS_PhyReq_Byte2: start 16, 8 bit, little-endian, init-value=0, base-type=uint8, implementation-data-type=DT_ECM_UDS_PhyReq_Byte2, update-indication-bit-position=-1, to MVCU
          signal ECM_UDS_PhyReq_Byte3: start 24, 8 bit, little-endian, init-value=0, base-type=uint8, implementation-data-type=DT_ECM_UDS_PhyReq_Byte3, update-indication-bit-position=-1, to MVCU
          signal ECM_UDS_PhyReq_Byte4: start 32, 8 bit, little-endian, init-value=0, base-type=uint8, implementation-data-type=DT_ECM_UDS_PhyReq_Byte4, update-indication-bit-position=-1, to MVCU
          signal ECM_UDS_PhyReq_Byte5: start 40, 8 bit, little-endian, init-value=0, base-type=uint8, implementation-data-type=DT_ECM_UDS_PhyReq_Byte5, update-indication-bit-position=-1, to MVCU
          signal ECM_UDS_PhyReq_Byte6: start 48, 8 bit, little-endian, init-value=0, base-type=uint8, implementation-data-type=DT_ECM_UDS_PhyReq_Byte6, update-indication-bit-position=-1, to MVCU
          signal ECM_UDS_PhyReq_Byte7: start 56, 8 bit, little-endian, init-value=0, base-type=uint8, implementation-data-type=DT_ECM_UDS_PhyReq_Byte7, update-indication-bit-position=-1, to MVCU
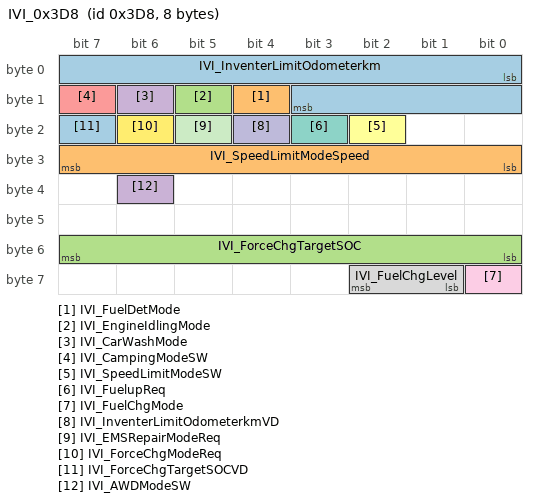
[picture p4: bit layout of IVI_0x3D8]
      frame IVI_0x3D8: id 0x3D8, to MVCU, frame-length=8, can-addressing-mode=STANDARD, can-fd-frame-support=true, can-frame-rx-behavior=CAN-FD
        carries pdu IVI_0x3D8: packing-byte-order=little-endian, start-position=0, update-indication-bit-position=-1
        pdu IVI_0x3D8: length=8, transmission-mode-false-timing=cyclic-timing={time-offset=0.0, time-period=0.2}, transmission-mode-true-timing=cyclic-timing={time-offset=0.0, time-period=0.2}
          transmission-mode-conditions:
            {data-filter={data-filter-type=NEW-IS-WITHIN, max=4000, min=0, offset=0}, i-signal-in-i-pdu=IVI_InventerLimitOdometerkm}
            {data-filter={data-filter-type=ALWAYS, max=1, min=0, offset=0}, i-signal-in-i-pdu=IVI_FuelDetMode}
            {data-filter={data-filter-type=ALWAYS, max=1, min=0, offset=0}, i-signal-in-i-pdu=IVI_EngineIdlingMode}
            {data-filter={data-filter-type=ALWAYS, max=1, min=0, offset=0}, i-signal-in-i-pdu=IVI_CarWashMode}
            {data-filter={data-filter-type=ALWAYS, max=1, min=0, offset=0}, i-signal-in-i-pdu=IVI_CampingModeSW}
            {data-filter={data-filter-type=ALWAYS, max=1, min=0, offset=0}, i-signal-in-i-pdu=IVI_SpeedLimitModeSW}
            {data-filter={data-filter-type=ALWAYS, max=1, min=0, offset=0}, i-signal-in-i-pdu=IVI_FuelupReq}
            {data-filter={data-filter-type=ALWAYS, max=3, min=0, offset=0}, i-signal-in-i-pdu=IVI_FuelChgLevel}
            {data-filter={data-filter-type=ALWAYS, max=1, min=0, offset=0}, i-signal-in-i-pdu=IVI_FuelChgMode}
            {data-filter={data-filter-type=ALWAYS, max=1, min=0, offset=0}, i-signal-in-i-pdu=IVI_InventerLimitOdometerkmVD}
            {data-filter={data-filter-type=ALWAYS, max=1, min=0, offset=0}, i-signal-in-i-pdu=IVI_EMSRepairModeReq}
            {data-filter={data-filter-type=ALWAYS, max=1, min=0, offset=0}, i-signal-in-i-pdu=IVI_ForceChgModeReq}
            {data-filter={data-filter-type=ALWAYS, max=1, min=0, offset=0}, i-signal-in-i-pdu=IVI_ForceChgTargetSOCVD}
            {data-filter={data-filter-type=ALWAYS, max=180, min=1, offset=0}, i-signal-in-i-pdu=IVI_SpeedLimitModeSpeed}
            {data-filter={data-filter-type=ALWAYS, max=100, min=0, offset=0}, i-signal-in-i-pdu=IVI_ForceChgTargetSOC}
          signal IVI_InventerLimitOdometerkm: start 0, 12 bit, little-endian, init-value=0, base-type=uint16, implementation-data-type=DT_IVI_InventerLimitOdometerkm, update-indication-bit-position=-1, to MVCU
          signal IVI_FuelDetMode: start 12, 1 bit, little-endian, init-value=0, base-type=uint8, implementation-data-type=DT_IVI_FuelDetMode, update-indication-bit-position=-1, to MVCU
          signal IVI_EngineIdlingMode: start 13, 1 bit, little-endian, init-value=0, base-type=uint8, implementation-data-type=DT_IVI_EngineIdlingMode, update-indication-bit-position=-1, to MVCU
          signal IVI_CarWashMode: start 14, 1 bit, little-endian, init-value=0, base-type=uint8, implementation-data-type=DT_IVI_CarWashMode, update-indication-bit-position=-1, to MVCU
          signal IVI_CampingModeSW: start 15, 1 bit, little-endian, init-value=0, base-type=uint8, implementation-data-type=DT_IVI_CampingModeSW, update-indication-bit-position=-1, to MVCU
          signal IVI_SpeedLimitModeSW: start 18, 1 bit, little-endian, init-value=0, base-type=uint8, implementation-data-type=DT_IVI_SpeedLimitModeSW, update-indication-bit-position=-1, to MVCU
          signal IVI_FuelupReq: start 19, 1 bit, little-endian, init-value=0, base-type=uint8, implementation-data-type=DT_IVI_FuelupReq, update-indication-bit-position=-1, to MVCU
          signal IVI_FuelChgLevel: start 57, 2 bit, little-endian, init-value=0, base-type=uint8, implementation-data-type=DT_IVI_FuelChgLevel, update-indication-bit-position=-1, to MVCU
          signal IVI_FuelChgMode: start 56, 1 bit, little-endian, init-value=0, base-type=uint8, implementation-data-type=DT_IVI_FuelChgMode, update-indication-bit-position=-1, to MVCU
          signal IVI_InventerLimitOdometerkmVD: start 20, 1 bit, little-endian, init-value=0, base-type=uint8, implementation-data-type=DT_IVI_InventerLimitOdometerkmVD, update-indication-bit-position=-1, to MVCU
          signal IVI_EMSRepairModeReq: start 21, 1 bit, little-endian, init-value=0, base-type=uint8, implementation-data-type=DT_IVI_EMSRepairModeReq, update-indication-bit-position=-1, to MVCU
          signal IVI_ForceChgModeReq: start 22, 1 bit, little-endian, init-value=0, base-type=uint8, implementation-data-type=DT_IVI_ForceChgModeReq, update-indication-bit-position=-1, to MVCU
          signal IVI_ForceChgTargetSOCVD: start 23, 1 bit, little-endian, init-value=0, base-type=uint8, implementation-data-type=DT_IVI_ForceChgTargetSOCVD, update-indication-bit-position=-1, to MVCU
          signal IVI_SpeedLimitModeSpeed: start 24, 8 bit, little-endian, init-value=0, base-type=uint8, implementation-data-type=DT_IVI_SpeedLimitModeSpeed, update-indication-bit-position=-1, to MVCU
          signal IVI_ForceChgTargetSOC: start 48, 8 bit, little-endian, init-value=0, base-type=uint8, implementation-data-type=DT_IVI_ForceChgTargetSOC, update-indication-bit-position=-1, to MVCU
          signal IVI_AWDModeSW: start 38, 1 bit, little-endian, init-value=0, base-type=uint8, update-indication-bit-position=-1, to MVCU
      frame UDS_Fun_Rx_7DF_MCUM: id 0x7DF, to MVCU, frame-length=64, can-addressing-mode=STANDARD, can-fd-frame-support=true, can-frame-rx-behavior=CAN-FD
        carries pdu UDS_Fun_Rx_7DF_MCUM: packing-byte-order=big-endian, start-position=7, update-indication-bit-position=-1
        dcm i pdu UDS_Fun_Rx_7DF_MCUM: length=64, diag-pdu-type=DIAG-RESPONSE
